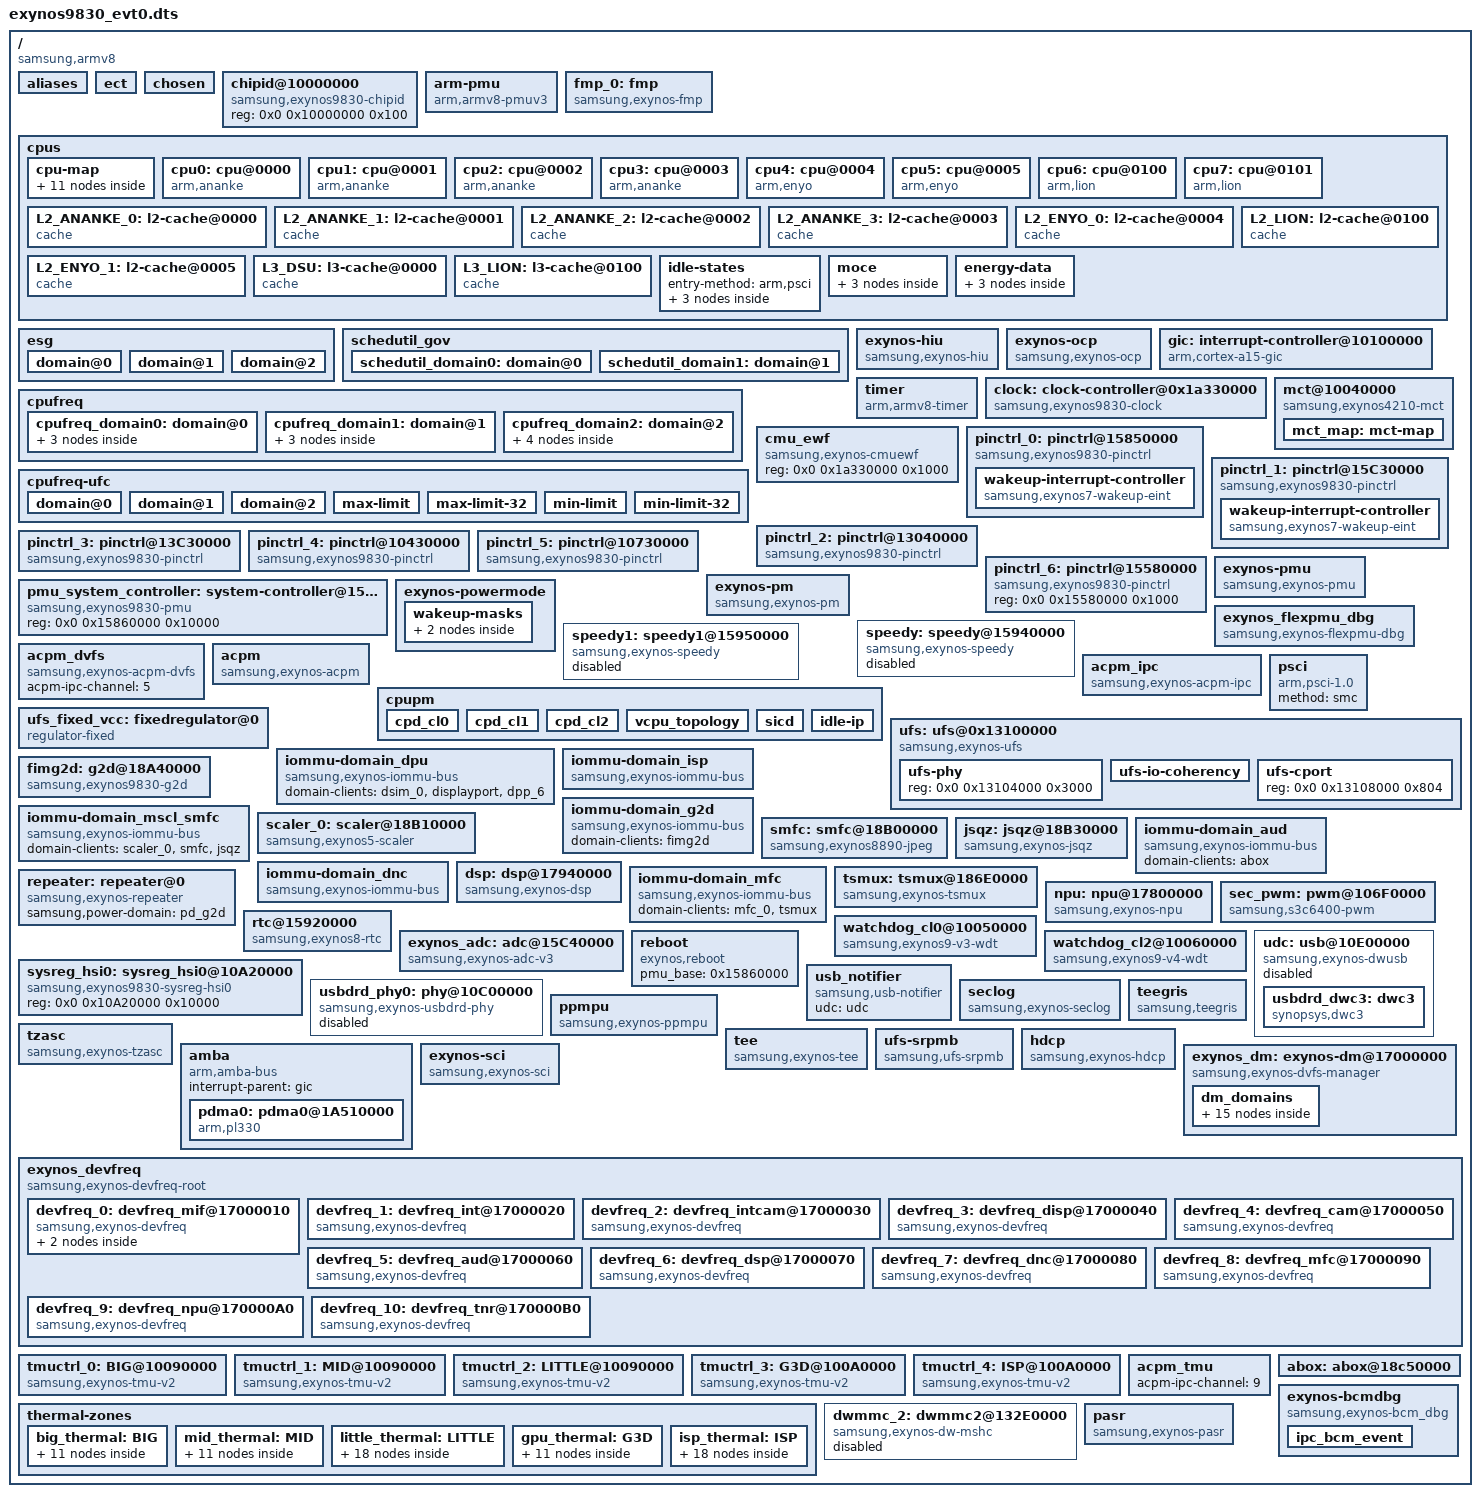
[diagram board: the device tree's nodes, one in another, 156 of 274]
/*
 * SAMSUNG EXYNOS9830 SoC device tree source
 *
 * Copyright (c) 2014 Samsung Electronics Co., Ltd.
 *		http://www.samsung.com
 *
 * SAMSUNG EXYNOS9830 SoC device nodes are listed in this file.
 * EXYNOS based board files can include this file and provide
 * values for board specfic bindings.
 *
 * This program is free software; you can redistribute it and/or modify
 * it under the terms of the GNU General Public License version 2 as
 * published by the Free Software Foundation.
 */

/dts-v1/;
#include <dt-bindings/interrupt-controller/arm-gic.h>
#include <dt-bindings/interrupt-controller/exynos9830_evt0.h>
#include <dt-bindings/soc/samsung/exynos-bcm_dbg.h>
#include "exynos9830-pinctrl.dtsi"
#include "exynos9830-rmem.dtsi"
#include "exynos9830_evt0-sysmmu.dtsi"
#include <dt-bindings/clock/exynos9830_evt0.h>
#include "exynos9830-usi.dtsi"
#include "exynos9830-pm-domains_evt0.dtsi"
#include "exynos9830_evt0-pmucal-dbg.dtsi"
#include "exynos9830-audio.dtsi"
#include <dt-bindings/ufs/ufs.h>
#include "exynos9830-debug.dtsi"
#include "exynos9830-mali.dtsi"
#include "exynos9830_evt0-bts.dtsi"
#include "exynos9830-dpu.dtsi"
#include "exynos9830_evt0-mfc.dtsi"
#include <dt-bindings/soc/samsung/exynos9830-dm.h>
#include <dt-bindings/soc/samsung/exynos9830-devfreq.h>
#include <dt-bindings/thermal/thermal.h>
#include "exynos9830-pcie.dtsi"
#include "exynos9830_evt0-camera.dtsi"
#include "exynos9830-ems.dtsi"

/ {
	compatible = "samsung,armv8", "samsung,exynos990";
	dtb-hw_rev = <0>;
	dtb-hw_rev_end = <255>;
	interrupt-parent = <&gic>;
	#address-cells = <2>;
	#size-cells = <1>;

	aliases {
		pinctrl0 = &pinctrl_0;
		pinctrl1 = &pinctrl_1;
		pinctrl2 = &pinctrl_2;
		pinctrl3 = &pinctrl_3;
		pinctrl4 = &pinctrl_4;
		pinctrl5 = &pinctrl_5;
		pinctrl6 = &pinctrl_6;
		fmp0 = &fmp_0;
		mshc2 = &dwmmc_2;
		scaler0 = &scaler_0;
		mfc0 = &mfc_0;
	};

	ect {
		parameter_address = <0x90000000>;
		parameter_size = <0x4B000>;
	};

	chosen: chosen {
//		bootargs = "earlycon=exynos4210,0x10540000 console=ttySAC0,115200n8 root=/dev/ram0 rw ramdisk=8192 initrd=0x84000000,8M init=/linuxrc mem=512M clk_ignore_unused";
		bootargs = "androidboot.dtbo_idx=0 bcm_setup=0xffffff80f8e00000 pmic_info=0x3 ccic_info=0x1 firmware_class.path=/vendor/firmware reserve-fimc=0xffffff90f9fe0000 nohugeiomap epx_activate=true fpsimd_check_context=y";
		linux,initrd-start = <0x84000000>;
		linux,initrd-end = <0x841FFFFF>;
	};


	chipid@10000000 {
		compatible = "samsung,exynos9830-chipid";
		reg = <0x0 0x10000000 0x100>;
	};

	arm-pmu {
		compatible = "arm,armv8-pmuv3";
		interrupts = <0 INTREQ__CPUCL0_PMUIRQ_0 4>,
			   <0 INTREQ__CPUCL0_PMUIRQ_1 4>,
			   <0 INTREQ__CPUCL0_PMUIRQ_2 4>,
			   <0 INTREQ__CPUCL0_PMUIRQ_3 4>,
			   <0 INTREQ__CPUCL0_PMUIRQ_4 4>,
			   <0 INTREQ__CPUCL0_PMUIRQ_5 4>,
			   <0 INTREQ__CPUCL2_PMUIRQ_0 4>,
			   <0 INTREQ__CPUCL2_PMUIRQ_1 4>;

		interrupt-affinity = <&cpu0>,
					<&cpu1>,
					<&cpu2>,
					<&cpu3>,
					<&cpu4>,
					<&cpu5>,
					<&cpu6>,
					<&cpu7>;
	};

	fmp_0: fmp {
		compatible = "samsung,exynos-fmp";
	};

	cpus {
		#address-cells = <2>;
		#size-cells = <0>;

		cpu-map {
			cluster0 {
				core0 {
					cpu = <&cpu0>;
				};
				core1 {
					cpu = <&cpu1>;
				};
				core2 {
					cpu = <&cpu2>;
				};
				core3 {
					cpu = <&cpu3>;
				};
			};

			cluster1 {
				core0 {
					cpu = <&cpu4>;
				};
				core1 {
					cpu = <&cpu5>;
				};
			};

			cluster2 {
				core0 {
					cpu = <&cpu6>;
				};
				core1 {
					cpu = <&cpu7>;
				};
			};
		};

		cpu0: cpu@0000 {
			device_type = "cpu";
			compatible = "arm,ananke", "arm,armv8";
			reg = <0x0 0x0000>;
			enable-method = "psci";
			cpu-idle-states = <&ANANKE_CPU_SLEEP>;
			sched-energy-data = <&ANANKE_ENERGY>;
			i-cache-size = <0x8000>;	/* 32KB */
			i-cache-line-size = <64>;
			i-cache-sets = <128>;
			d-cache-size = <0x8000>;	/* 32KB */
			d-cache-line-size = <64>;
			d-cache-sets = <128>;
			next-level-cache = <&L2_ANANKE_0>;
		};
		cpu1: cpu@0001 {
			device_type = "cpu";
			compatible = "arm,ananke", "arm,armv8";
			reg = <0x0 0x0001>;
			enable-method = "psci";
			cpu-idle-states = <&ANANKE_CPU_SLEEP>;
			sched-energy-data = <&ANANKE_ENERGY>;
			i-cache-size = <0x8000>;	/* 32KB */
			i-cache-line-size = <64>;
			i-cache-sets = <128>;
			d-cache-size = <0x8000>;	/* 32KB */
			d-cache-line-size = <64>;
			d-cache-sets = <128>;
			next-level-cache = <&L2_ANANKE_1>;
		};
		cpu2: cpu@0002 {
			device_type = "cpu";
			compatible = "arm,ananke", "arm,armv8";
			reg = <0x0 0x0002>;
			enable-method = "psci";
			cpu-idle-states = <&ANANKE_CPU_SLEEP>;
			sched-energy-data = <&ANANKE_ENERGY>;
			i-cache-size = <0x8000>;	/* 32KB */
			i-cache-line-size = <64>;
			i-cache-sets = <128>;
			d-cache-size = <0x8000>;	/* 32KB */
			d-cache-line-size = <64>;
			d-cache-sets = <128>;
			next-level-cache = <&L2_ANANKE_2>;
		};
		cpu3: cpu@0003 {
			device_type = "cpu";
			compatible = "arm,ananke", "arm,armv8";
			reg = <0x0 0x0003>;
			enable-method = "psci";
			cpu-idle-states = <&ANANKE_CPU_SLEEP>;
			sched-energy-data = <&ANANKE_ENERGY>;
			i-cache-size = <0x8000>;	/* 32KB */
			i-cache-line-size = <64>;
			i-cache-sets = <128>;
			d-cache-size = <0x8000>;	/* 32KB */
			d-cache-line-size = <64>;
			d-cache-sets = <128>;
			next-level-cache = <&L2_ANANKE_3>;
		};
		cpu4: cpu@0004 {
			device_type = "cpu";
			compatible = "arm,enyo", "arm,armv8";
			reg = <0x0 0x0004>;
			enable-method = "psci";
			cpu-idle-states = <&ENYO_CPU_SLEEP>;
			sched-energy-data = <&ENYO_ENERGY>;
			i-cache-size = <0x10000>;	/* 64KB */
			i-cache-line-size = <64>;
			i-cache-sets = <256>;
			d-cache-size = <0x10000>;	/* 64KB */
			d-cache-line-size = <64>;
			d-cache-sets = <256>;
			next-level-cache = <&L2_ENYO_0>;
		};
		cpu5: cpu@0005 {
			device_type = "cpu";
			compatible = "arm,enyo", "arm,armv8";
			reg = <0x0 0x0005>;
			enable-method = "psci";
			cpu-idle-states = <&ENYO_CPU_SLEEP>;
			sched-energy-data = <&ENYO_ENERGY>;
			i-cache-size = <0x10000>;	/* 64KB */
			i-cache-line-size = <64>;
			i-cache-sets = <256>;
			d-cache-size = <0x10000>;	/* 64KB */
			d-cache-line-size = <64>;
			d-cache-sets = <256>;
			next-level-cache = <&L2_ENYO_1>;
		};
		cpu6: cpu@0100 {
			device_type = "cpu";
			compatible = "arm,lion", "arm,armv8";
			reg = <0x0 0x0100>;
			enable-method = "psci";
			cpu-idle-states = <&LION_CPU_SLEEP>;
			sched-energy-data = <&LION_ENERGY>;
			i-cache-size = <0x10000>;	/* 64KB */
			i-cache-line-size = <128>;
			i-cache-sets = <128>;
			d-cache-size = <0x10000>;	/* 64KB */
			d-cache-line-size = <64>;
			d-cache-sets = <256>;
			next-level-cache = <&L2_LION>;
		};
		cpu7: cpu@0101 {
			device_type = "cpu";
			compatible = "arm,lion", "arm,armv8";
			reg = <0x0 0x0101>;
			enable-method = "psci";
			cpu-idle-states = <&LION_CPU_SLEEP>;
			sched-energy-data = <&LION_ENERGY>;
			i-cache-size = <0x10000>;	/* 64KB */
			i-cache-line-size = <128>;
			i-cache-sets = <128>;
			d-cache-size = <0x10000>;	/* 64KB */
			d-cache-line-size = <64>;
			d-cache-sets = <256>;
			next-level-cache = <&L2_LION>;
		};

		L2_ANANKE_0: l2-cache@0000 {
			compatible = "cache";
			cache-level = <2>;
			cache-size = <0x10000>;		/* 64KB */
			cache-line-size = <64>;
			cache-sets = <256>;
			next-level-cache = <&L3_DSU>;
		};
		L2_ANANKE_1: l2-cache@0001 {
			compatible = "cache";
			cache-level = <2>;
			cache-size = <0x10000>;		/* 64KB */
			cache-line-size = <64>;
			cache-sets = <256>;
			next-level-cache = <&L3_DSU>;
		};
		L2_ANANKE_2: l2-cache@0002 {
			compatible = "cache";
			cache-level = <2>;
			cache-size = <0x10000>;		/* 64KB */
			cache-line-size = <64>;
			cache-sets = <256>;
			next-level-cache = <&L3_DSU>;
		};
		L2_ANANKE_3: l2-cache@0003 {
			compatible = "cache";
			cache-level = <2>;
			cache-size = <0x10000>;		/* 64KB */
			cache-line-size = <64>;
			cache-sets = <256>;
			next-level-cache = <&L3_DSU>;
		};
		L2_ENYO_0: l2-cache@0004 {
			compatible = "cache";
			cache-level = <2>;
			cache-size = <0x40000>;		/* 256KB */
			cache-line-size = <64>;
			cache-sets = <512>;
			next-level-cache = <&L3_DSU>;
		};
		L2_ENYO_1: l2-cache@0005 {
			compatible = "cache";
			cache-level = <2>;
			cache-size = <0x40000>;		/* 256KB */
			cache-line-size = <64>;
			cache-sets = <512>;
			next-level-cache = <&L3_DSU>;
		};
		L2_LION: l2-cache@0100 {
			compatible = "cache";
			cache-level = <2>;
			cache-size = <0x200000>;	/* 2MB */
			cache-line-size = <64>;
			cache-sets = <4096>;
			next-level-cache = <&L3_LION>;
		};
		L3_DSU: l3-cache@0000 {
			compatible = "cache";
			cache-level = <3>;
			cache-line-size = <64>;
			cache-sets = <1024>;
			cache-size = <0x100000>;	/* 1MB */
		};
		L3_LION: l3-cache@0100 {
			compatible = "cache";
			cache-level = <3>;
			cache-line-size = <64>;
			cache-sets = <4096>;
			cache-size = <0x300000>;	/* 3MB */
		};

		idle-states {
			entry-method = "arm,psci";

			ANANKE_CPU_SLEEP: ananke-cpu-sleep {
				idle-state-name = "c2";
				compatible = "exynos,idle-state";
				arm,psci-suspend-param = <0x0010000>;
				entry-latency-us = <70>;
				exit-latency-us = <160>;
				min-residency-us = <2000>;
				status = "okay";
				moce-weights = <100>;
				moce-factors = <&ANANKE_FREQ_FACTOR>;
			};

			ENYO_CPU_SLEEP: enyo-cpu-sleep {
				idle-state-name = "c2";
				compatible = "exynos,idle-state";
				arm,psci-suspend-param = <0x0010000>;
				entry-latency-us = <150>;
				exit-latency-us = <190>;
				min-residency-us = <2500>;
				status = "okay";
				moce-weights = <100>;
				moce-factors = <&ENYO_FREQ_FACTOR>;
			};

			LION_CPU_SLEEP: lion-cpu-sleep {
				idle-state-name = "c2";
				compatible = "exynos,idle-state";
				arm,psci-suspend-param = <0x0010000>;
				entry-latency-us = <235>;
				exit-latency-us = <220>;
				min-residency-us = <3500>;
				status = "okay";
				moce-weights = <100>;
				moce-factors = <&LION_FREQ_FACTOR>;
			};
		};

		moce {
			/* factor table format: [ratio][factor][ratio]...[ratio] */
			ANANKE_FREQ_FACTOR: ananke-freq-factor {
				domain = <0>;
				type = <0>;
				ratio-table = <100>;
			};
			ENYO_FREQ_FACTOR: enyo-freq-factor {
				domain = <1>;
				type = <0>;
				ratio-table = <100>;
			};
			LION_FREQ_FACTOR: lion-freq-factor {
				domain = <2>;
				type = <0>;
				ratio-table = <100>;
			};
		};

		energy-data {
			ANANKE_ENERGY: ananke-energy {
				mips-per-mhz = <2776>;
				power-coefficient = <112>;
				mips-per-mhz-s = <2221>;
				power-coefficient-s = <99>;
				static-power-coefficient = <56>;

				efficiency-weight = <100>;
				efficiency-weight-perf = <200>;
			};
			ENYO_ENERGY: enyo-energy {
				mips-per-mhz = <6618>;
				power-coefficient = <331>;
				mips-per-mhz-s = <4434>;
				power-coefficient-s = <258>;
				static-power-coefficient = <69>;

				efficiency-weight = <200>;
				efficiency-weight-perf = <200>;
			};
			LION_ENERGY: lion-energy {
				mips-per-mhz = <8248>;
				power-coefficient = <908>;
				mips-per-mhz-s = <3382>;
				power-coefficient-s = <590>;
				static-power-coefficient = <291>;

				efficiency-weight = <33>;
				efficiency-weight-perf = <300>;
			};
		};
	};

	esg {
		domain@0 {
			device_type = "esgov-pol0";
			shared-cpus = "0-3";
			pm_qos-min-class = <3>;
			pm_qos-max-class = <4>;
			step = <10>;
		};
		domain@1 {
			device_type = "esgov-pol4";
			shared-cpus = "4-5";
			pm_qos-min-class = <5>;
			pm_qos-max-class = <6>;
			step = <8>;
		};
		domain@2 {
			device_type = "esgov-pol6";
			shared-cpus = "6-7";
			pm_qos-min-class = <7>;
			pm_qos-max-class = <8>;
			step = <10>;
		};
	};

	schedutil_gov {
		schedutil_domain0: domain@0 {
			device_type = "schedutil-domain";
			shared-cpus = "0-3";

			enabled = <0>;          /* Disabled */
			qos_min_class = <3>;
		};

		schedutil_domain1: domain@1 {
			device_type = "schedutil-domain";
			shared-cpus = "4-5";

			enabled = <1>;          /* Enabled */
			expired_time = <80>;    /* 80ms */
			qos_min_class = <5>;
		};
	};

	cpufreq {
		cpufreq_domain0: domain@0 {
			device_type = "cpufreq-domain";
			sibling-cpus = "0-3";
			cal-id = <ACPM_DVFS_CPUCL0>;
			dm-type = <DM_CPU_CL0>;

			max-freq = <1586000>;
			min-freq = <182000>;

			/* PM QoS Class ID*/
			pm_qos-min-class = <3>;
			pm_qos-max-class = <4>;

			user-default-qos = <806000>;
			user-boost = <0>;

			#cooling-cells = <2>; /* min followed by max */

			dm-constraints {
				mif-perf {
					const-type = <CONSTRAINT_MIN>;
					dm-type = <DM_MIF>;
						/* cpu      mif */
					table = < 2106000 0
						2002000 0
						1950000 0
						1846000 0
						1742000 0
						1586000 0
						1456000 0
						1300000 0
						1157000 0
						1053000 0
						 949000 0
						 806000 0
						 650000 0
						 546000 0
						 442000 0
						 351000 0
						 182000 0
						>;
				};
			};

			slack_timer {
				device_type = "slack-timer-domain";
			};
		};

		cpufreq_domain1: domain@1 {
			device_type = "cpufreq-domain";
			sibling-cpus = "4-5";
			cal-id = <ACPM_DVFS_CPUCL1>;
			dm-type = <DM_CPU_CL1>;

			max-freq = <1898000>;
			min-freq = <377000>;

			/* PM QoS Class ID*/
			pm_qos-min-class = <5>;
			pm_qos-max-class = <6>;

			user-default-qos = <845000>;
			user-boost = <1>;

			#cooling-cells = <2>; /* min followed by max */

			dm-constraints {
				mif-perf {
					const-type = <CONSTRAINT_MIN>;
					dm-type = <DM_MIF>;
						/* cpu     mif */
					table = < 2600000 1794000
						2504000 1794000
						2400000 1794000
						2314000 1794000
						2210000 1794000
						2106000 1539000
						2002000 1539000
						1898000 0
						1794000 0
						1690000 0
						1586000 0
						1508000 0
						1404000 0
						1222000 0
						1066000 0
						 962000 0
						 845000 0
						 754000 0
						 650000 0
						 507000 0
						 377000 0
						>;
				};
			};

			slack_timer {
				device_type = "slack-timer-domain";
				expired_time = <80>;    /* 80ms */
			};
		};

		cpufreq_domain2: domain@2 {
			device_type = "cpufreq-domain";
			sibling-cpus = "6-7";
			cal-id = <ACPM_DVFS_CPUCL2>;
			dm-type = <DM_CPU_CL2>;
			need-awake;

			max-freq = <1482000>;
			min-freq = <546000>;

			/* PM QoS Class ID*/
			pm_qos-min-class = <7>;
			pm_qos-max-class = <8>;

			user-default-qos = <962000>;
			user-boost = <2>;

			#cooling-cells = <2>; /* min followed by max */

			dm-constraints {
				mif-perf {
					const-type = <CONSTRAINT_MIN>;
					dm-type = <DM_MIF>;
					/*  cpu     mif  */
					table = < 3016000 1794000
						2834000 1794000
						2730000 1794000
						2626000 1794000
						2522000 1794000
						2418000 1794000
						2314000 1794000
						2210000 1794000
						2002000 1539000
						1898000 0
						1794000 0
						1690000 0
						1586000 0
						1482000 0
						1378000 0
						1274000 0
						1170000 0
						1066000 0
						962000  0
						888000 0
						754000 0
						650000 0
						546000 0
						>;
				};
				mif-skew {
					guidance;
					const-type = <CONSTRAINT_MIN>;
					dm-type = <DM_MIF>;
					ect-name = "CPUCL2";
				};
			};

			slack_timer {
				device_type = "slack-timer-domain";

				enabled = <1>;          /* Enabled */
				expired_time = <80>;    /* 80ms */
			};
		};
	};

	cpufreq-ufc {
		/* Ctrl Type */
		#define PM_QOS_MIN_LIMIT		0
		#define PM_QOS_MIN_WO_BOOST_LIMIT	1
		#define PM_QOS_MAX_LIMIT		2
		/* Execution Mode */
		#define AARCH64_MODE			0
		#define AARCH32_MODE			1

		device_type = "cpufreq_ufc";
		table-col = <4>;
		table-row = <42>;

		domain@0 {
			device_type = "ufc_domain";
			shared-cpus = "0-3";
			pm_qos-min-class = <3>;
			pm_qos-max-class = <4>;
		};
		domain@1 {
			device_type = "ufc_domain";
			shared-cpus = "4-5";
			pm_qos-min-class = <5>;
			pm_qos-max-class = <6>;
		};
		domain@2 {
			device_type = "ufc_domain";
			shared-cpus = "6-7";
			pm_qos-min-class = <7>;
			pm_qos-max-class = <8>;
		};
		max-limit {
			device_type = "ufc_table";
			ctrl-type = <PM_QOS_MAX_LIMIT>;
			sse-mode = <AARCH64_MODE>;
			      /* Vfreq    big      Med	Lit */
			table = <
				2730000	2730000	2600000	2002000
				2623359	2626000	2600000	2002000
				2519384	2522000	2600000	2002000
				2415410	2418000	2600000	2002000
				2311435	2314000	2600000	2002000
				2207460	2210000	2600000	2002000
				2170136	2106000	2600000	2002000
				2103486	2002000	2600000	2002000
				2090156	1898000	2600000	2002000
				2002177	1794000	2600000	2002000
				1999511	1794000	2504000	2002000
				1930195	1690000	2504000	2002000
				1895537	1690000	2400000	2002000
				1844882	1586000	2400000	2002000
				1791562	1482000	2400000	2002000
				1756904	1482000	2314000	2002000
				1687587	1378000	2314000	2002000
				1671591	1378000	2210000	2002000
				1599609	1274000	2210000	1950000
				1583613	1170000	2210000	1846000
				1495634	1170000	2106000	1846000
				1479638	1066000	2106000	1846000
				1410322	962000	2106000	1742000
				1375664	962000	2106000	1742000
				1322343	962000	2002000	1742000
				1271689	962000	2002000	1742000
				1258359	962000	2002000	1742000
				1170380	888000	2002000	1742000
				1167714	888000	2002000	1586000
				1063740	888000	1898000	1586000
				1018417	888000	1794000	1456000
				959765	888000	1690000	1456000
				887783	888000	1586000	1300000
				855791	888000	1508000	1300000
				802470	888000	1404000	1300000
				751816	888000	1222000	1300000
				703828	754000	1066000	1300000
				647841	0	962000	1300000
				629179	0	845000	1300000
				543867	0	754000	1300000
				541201	0	650000	1300000
				421230	0	507000	1300000
				/* filled little freq automatically */
				>;
		};
		max-limit-32 {
			device_type = "ufc_table";
			ctrl-type = <PM_QOS_MAX_LIMIT>;
			sse-mode = <AARCH32_MODE>;
			      /* Vfreq    big      Lit */
			table = <
				2730000	2730000	2600000	2002000
				2623359	2626000	2600000	2002000
				2519384	2522000	2600000	2002000
				2415410	2418000	2600000	2002000
				2311435	2314000	2600000	2002000
				2207460	2210000	2600000	2002000
				2170136	2106000	2600000	2002000
				2103486	2002000	2600000	2002000
				2090156	1898000	2600000	2002000
				2002177	1794000	2600000	2002000
				1999511	1690000	2600000	2002000
				1930195	1586000	2600000	2002000
				1895537	1586000	2504000	2002000
				1844882	1482000	2504000	2002000
				1791562	1482000	2400000	2002000
				1756904	1378000	2400000	2002000
				1687587	1274000	2400000	2002000
				1671591	1170000	2400000	2002000
				1599609	1170000	2314000	2002000
				1583613	1066000	2314000	2002000
				1495634	962000	2314000	2002000
				1479638	962000	2210000	2002000
				1410322	888000	2210000	2002000
				1375664	754000	2210000	2002000
				1322343	754000	2210000	2002000
				1271689	754000	2210000	2002000
				1258359	754000	2210000	2002000
				1170380	754000	2106000	1950000
				1167714	754000	2002000	1846000
				1063740	754000	1898000	1742000
				1018417	754000	1794000	1586000
				959765	754000	1690000	1586000
				887783	754000	1586000	1456000
				855791	754000	1508000	1456000
				802470	754000	1404000	1456000
				751816	754000	1222000	1300000
				703828	754000	1066000	1300000
				647841	0	962000	1300000
				629179	0	845000	1300000
				543867	0	754000	1300000
				541201	0	650000	1300000
				421230	0	507000	1300000
				/* filled little freq automatically */
				>;
		};
		min-limit {
			device_type = "ufc_table";
			ctrl-type = <PM_QOS_MIN_LIMIT>;
			sse-mode = <AARCH64_MODE>;
			      /* Vfreq    big      Lit */
			table = <
				2730000	2730000	2600000	2002000
				2623359	2626000	2600000	2002000
				2519384	2522000	2600000	2002000
				2415410	2418000	2600000	2002000
				2311435	2314000	2600000	2002000
				2207460	2210000	2600000	2002000
				2170136	2210000	2600000	2002000
				2103486	2106000	2600000	2002000
				2090156	2106000	2504000	2002000
				2002177	2106000	2400000	2002000
				1999511	2002000	2400000	2002000
				1930195	2002000	2314000	2002000
				1895537	1898000	2314000	806000
				1844882	1898000	2210000	806000
				1791562	1794000	2210000	806000
				1756904	1794000	2106000	806000
				1687587	1690000	2106000	806000
				1671591	1690000	2002000	806000
				1599609	1690000	1898000	806000
				1583613	1586000	1898000	806000
				1495634	1586000	1794000	806000
				1479638	1482000	1794000	806000
				1410322	1482000	1690000	806000
				1375664	1378000	1690000	806000
				1322343	1378000	1586000	806000
				1271689	1274000	1586000	806000
				1258359	1274000	1508000	806000
				1170380	1274000	1404000	806000
				1167714	1170000	1404000	806000
				1063740	1066000	1404000	806000
				1018417	1066000	1222000	806000
				959765	962000	1222000	806000
				887783	962000	1066000	806000
				855791	888000	1066000	806000
				802470	888000	962000	806000
				751816	754000	962000	806000
				703828	754000	845000	806000
				647841	650000	845000	806000
				629179	650000	754000	806000
				543867	546000	754000	806000
				541201	546000	650000	806000
				421230	546000	507000	806000
				/* filled little freq automatically */
				>;
		};
		min-limit-32 {
			device_type = "ufc_table";
			ctrl-type = <PM_QOS_MIN_LIMIT>;
			sse-mode = <AARCH32_MODE>;
			table = <
				2730000	2730000	2600000	2002000
				2623359	2626000	2600000	2002000
				2519384	2626000	2600000	2002000
				2415410	2522000	2600000	2002000
				2311435	2522000	2504000	2002000
				2207460	2418000	2504000	2002000
				2170136	2418000	2400000	2002000
				2103486	2418000	2314000	2002000
				2090156	2314000	2314000	2002000
				2002177	2314000	2210000	2002000
				1999511	2210000	2210000	2002000
				1930195	2210000	2106000	2002000
				1895537	2106000	2106000	806000
				1844882	2106000	2002000	806000
				1791562	2002000	2002000	806000
				1756904	2002000	1898000	806000
				1687587	1898000	1898000	806000
				1671591	1898000	1794000	806000
				1599609	1794000	1794000	806000
				1583613	1794000	1690000	806000
				1495634	1690000	1690000	806000
				1479638	1690000	1586000	806000
				1410322	1586000	1586000	806000
				1375664	1586000	1508000	806000
				1322343	1482000	1508000	806000
				1271689	1482000	1404000	806000
				1258359	1378000	1404000	806000
				1170380	1274000	1404000	806000
				1167714	1274000	1222000	806000
				1063740	1170000	1222000	806000
				1018417	1170000	1066000	806000
				959765	1066000	1066000	806000
				887783	1066000	962000	806000
				855791	962000	962000	806000
				802470	888000	962000	806000
				751816	888000	845000	806000
				703828	888000	754000	806000
				647841	754000	754000	806000
				629179	754000	650000	806000
				543867	650000	650000	806000
				541201	546000	650000	806000
				421230	546000	507000	806000
				/* filled little freq automatically */
				>;
		};
	};

	exynos-hiu {
		compatible = "samsung,exynos-hiu";
		interrupts = <GIC_SPI INTREQ__CPUCL2_GCUIRQ IRQ_TYPE_LEVEL_HIGH>;
		boost-threshold = <1482000>;
		boost-max = <1482000>;
		cal-id = <ACPM_DVFS_CPUCL2>;
		sw-pbl = <0x57>;
		bl1-inc = <0>;
		bl2-inc = <0>;
		bl3-inc = <0>;
		tb-enabled;
		operation-mode = <0>;
		sibling-cpus = "6-7";
				/* PB  BL  PBL  PWR_THR_INC */
		config-table = <0x0 0x0 0x57 0x0        /* config A */
				0x1 0x2 0x79 0x0        /* config B */
				0x0 0x0 0x57 0x0        /* config C */
				0x0 0x0 0x57 0x0        /* config D */
				0x1 0x2 0x79 0x0        /* config E */
				0x0 0x0 0x57 0x0        /* config F */
				0x0 0x0 0x57 0x0        /* config G */
				0x1 0x2 0x79 0x0>;      /* config H */
	};

	exynos-ocp {
		compatible = "samsung,exynos-ocp";

		interrupts = <GIC_SPI INTREQ__CPUCL2_GCUIRQ IRQ_TYPE_LEVEL_HIGH>;

		sibling-cpus = "6-7";
		down-step = <1>;

		max-freq-wo-ocp = <1482000>;

		release-mode = <1>;             /* 0 : current meter, 1 : cpu utilization */
		release-threshold = <50>;       /* @current meter : current(A), @cpu load : capacity ratio(%) */
		release-duration = <15>;        /* msec */
	};


	gic:interrupt-controller@10100000 {
		compatible = "arm,cortex-a15-gic", "arm,cortex-a9-gic";
		#interrupt-cells = <3>;
		#address-cells = <0>;
		interrupt-controller;
		reg =	<0x0 0x10101000 0x1000>,
			<0x0 0x10102000 0x1000>,
			<0x0 0x10104000 0x2000>,
			<0x0 0x10106000 0x2000>;
		interrupts = <GIC_PPI 9 (GIC_CPU_MASK_SIMPLE(4) | IRQ_TYPE_LEVEL_HIGH)>;
	};

	timer {
	        compatible = "arm,armv8-timer";
		interrupts = <GIC_PPI 13
				(GIC_CPU_MASK_SIMPLE(8) | IRQ_TYPE_LEVEL_LOW)>,
			     <GIC_PPI 14
				(GIC_CPU_MASK_SIMPLE(8) | IRQ_TYPE_LEVEL_LOW)>,
			     <GIC_PPI 11
				(GIC_CPU_MASK_SIMPLE(8) | IRQ_TYPE_LEVEL_LOW)>,
			     <GIC_PPI 10
				(GIC_CPU_MASK_SIMPLE(8) | IRQ_TYPE_LEVEL_LOW)>;
	        clock-frequency = <26000000>;
		use-clocksource-only;
	};

	clock: clock-controller@0x1a330000 {
		compatible = "samsung,exynos9830-clock";
		reg = <0x0 0x1a330000 0x8000>;
		#clock-cells = <1>;
		acpm-ipc-channel = <0>;
	};

	cmu_ewf {
		compatible = "samsung,exynos-cmuewf";
		#address-cells = <2>;
		#size-cells = <1>;
		reg = <0x0 0x1a330000 0x1000>;
	};

	mct@10040000 {
		compatible = "samsung,exynos4210-mct";
		reg = <0x0 0x10040000 0x800>;
		interrupt-controller;
		#interrupt-cells = <1>;
		interrupt-parent = <&mct_map>;
		interrupts =	<0>, <1>, <2>, <3>,
				<4>, <5>, <6>, <7>,
				<8>, <9>, <10>, <11>;
		clocks = <&clock 1>, <&clock 15>;
		clock-names = "fin_pll", "mct";
		use-clockevent-only;

		mct_map: mct-map {
			#interrupt-cells = <1>;
			#address-cells = <0>;
			#size-cells = <0>;
			interrupt-map = <0 &gic 0 INTREQ__MCT_G0 IRQ_TYPE_LEVEL_HIGH>,
					<1 &gic 0 INTREQ__MCT_G1 IRQ_TYPE_LEVEL_HIGH>,
					<2 &gic 0 INTREQ__MCT_G2 IRQ_TYPE_LEVEL_HIGH>,
					<3 &gic 0 INTREQ__MCT_G3 IRQ_TYPE_LEVEL_HIGH>,
					<4 &gic 0 INTREQ__MCT_L0 IRQ_TYPE_LEVEL_HIGH>,
					<5 &gic 0 INTREQ__MCT_L1 IRQ_TYPE_LEVEL_HIGH>,
					<6 &gic 0 INTREQ__MCT_L2 IRQ_TYPE_LEVEL_HIGH>,
					<7 &gic 0 INTREQ__MCT_L3 IRQ_TYPE_LEVEL_HIGH>,
					<8 &gic 0 INTREQ__MCT_L4 IRQ_TYPE_LEVEL_HIGH>,
					<9 &gic 0 INTREQ__MCT_L5 IRQ_TYPE_LEVEL_HIGH>,
					<10 &gic 0 INTREQ__MCT_L6 IRQ_TYPE_LEVEL_HIGH>,
					<11 &gic 0 INTREQ__MCT_L7 IRQ_TYPE_LEVEL_HIGH>;
		};
	};

	/* ALIVE */
	pinctrl_0: pinctrl@15850000 {
		compatible = "samsung,exynos9830-pinctrl";
		reg = <0x0 0x15850000 0x1000>;
		interrupts = <GIC_SPI INTREQ__ALIVE_EINT0 IRQ_TYPE_LEVEL_HIGH>, <GIC_SPI INTREQ__ALIVE_EINT1 IRQ_TYPE_LEVEL_HIGH>,
			     <GIC_SPI INTREQ__ALIVE_EINT2 IRQ_TYPE_LEVEL_HIGH>, <GIC_SPI INTREQ__ALIVE_EINT3 IRQ_TYPE_LEVEL_HIGH>,
			     <GIC_SPI INTREQ__ALIVE_EINT4 IRQ_TYPE_LEVEL_HIGH>, <GIC_SPI INTREQ__ALIVE_EINT5 IRQ_TYPE_LEVEL_HIGH>,
			     <GIC_SPI INTREQ__ALIVE_EINT6 IRQ_TYPE_LEVEL_HIGH>, <GIC_SPI INTREQ__ALIVE_EINT7 IRQ_TYPE_LEVEL_HIGH>,
			     <GIC_SPI INTREQ__ALIVE_EINT8 IRQ_TYPE_LEVEL_HIGH>, <GIC_SPI INTREQ__ALIVE_EINT9 IRQ_TYPE_LEVEL_HIGH>,
			     <GIC_SPI INTREQ__ALIVE_EINT10 IRQ_TYPE_LEVEL_HIGH>, <GIC_SPI INTREQ__ALIVE_EINT11 IRQ_TYPE_LEVEL_HIGH>,
			     <GIC_SPI INTREQ__ALIVE_EINT12 IRQ_TYPE_LEVEL_HIGH>, <GIC_SPI INTREQ__ALIVE_EINT13 IRQ_TYPE_LEVEL_HIGH>,
			     <GIC_SPI INTREQ__ALIVE_EINT14 IRQ_TYPE_LEVEL_HIGH>, <GIC_SPI INTREQ__ALIVE_EINT15 IRQ_TYPE_LEVEL_HIGH>,
			     <GIC_SPI INTREQ__ALIVE_EINT16 IRQ_TYPE_LEVEL_HIGH>, <GIC_SPI INTREQ__ALIVE_EINT17 IRQ_TYPE_LEVEL_HIGH>,
			     <GIC_SPI INTREQ__ALIVE_EINT18 IRQ_TYPE_LEVEL_HIGH>, <GIC_SPI INTREQ__ALIVE_EINT19 IRQ_TYPE_LEVEL_HIGH>,
			     <GIC_SPI INTREQ__ALIVE_EINT20 IRQ_TYPE_LEVEL_HIGH>, <GIC_SPI INTREQ__ALIVE_EINT21 IRQ_TYPE_LEVEL_HIGH>,
			     <GIC_SPI INTREQ__ALIVE_EINT22 IRQ_TYPE_LEVEL_HIGH>, <GIC_SPI INTREQ__ALIVE_EINT23 IRQ_TYPE_LEVEL_HIGH>,
			     <GIC_SPI INTREQ__ALIVE_EINT24 IRQ_TYPE_LEVEL_HIGH>, <GIC_SPI INTREQ__ALIVE_EINT25 IRQ_TYPE_LEVEL_HIGH>,
			     <GIC_SPI INTREQ__ALIVE_EINT26 IRQ_TYPE_LEVEL_HIGH>, <GIC_SPI INTREQ__ALIVE_EINT27 IRQ_TYPE_LEVEL_HIGH>,
			     <GIC_SPI INTREQ__ALIVE_EINT28 IRQ_TYPE_LEVEL_HIGH>, <GIC_SPI INTREQ__ALIVE_EINT29 IRQ_TYPE_LEVEL_HIGH>,
			     <GIC_SPI INTREQ__ALIVE_EINT30 IRQ_TYPE_LEVEL_HIGH>, <GIC_SPI INTREQ__ALIVE_EINT31 IRQ_TYPE_LEVEL_HIGH>,
			     <GIC_SPI INTREQ__ALIVE_EINT32 IRQ_TYPE_LEVEL_HIGH>, <GIC_SPI INTREQ__ALIVE_EINT33 IRQ_TYPE_LEVEL_HIGH>;

		wakeup-interrupt-controller {
			compatible = "samsung,exynos7-wakeup-eint";
		};
	};

	/* CMGP */
	pinctrl_1: pinctrl@15C30000{
		compatible = "samsung,exynos9830-pinctrl";
		reg = <0x0 0x15C30000 0x1000>;
		interrupts = <GIC_SPI INTREQ__EXT_INTM04 IRQ_TYPE_LEVEL_HIGH>, <GIC_SPI INTREQ__EXT_INTM05 IRQ_TYPE_LEVEL_HIGH>,
			     <GIC_SPI INTREQ__EXT_INTM06 IRQ_TYPE_LEVEL_HIGH>, <GIC_SPI INTREQ__EXT_INTM07 IRQ_TYPE_LEVEL_HIGH>,
			     <GIC_SPI INTREQ__EXT_INTM08 IRQ_TYPE_LEVEL_HIGH>, <GIC_SPI INTREQ__EXT_INTM09 IRQ_TYPE_LEVEL_HIGH>,
			     <GIC_SPI INTREQ__EXT_INTM10 IRQ_TYPE_LEVEL_HIGH>, <GIC_SPI INTREQ__EXT_INTM11 IRQ_TYPE_LEVEL_HIGH>,
			     <GIC_SPI INTREQ__EXT_INTM12 IRQ_TYPE_LEVEL_HIGH>, <GIC_SPI INTREQ__EXT_INTM13 IRQ_TYPE_LEVEL_HIGH>,
			     <GIC_SPI INTREQ__EXT_INTM14 IRQ_TYPE_LEVEL_HIGH>, <GIC_SPI INTREQ__EXT_INTM15 IRQ_TYPE_LEVEL_HIGH>,
			     <GIC_SPI INTREQ__EXT_INTM16 IRQ_TYPE_LEVEL_HIGH>, <GIC_SPI INTREQ__EXT_INTM17 IRQ_TYPE_LEVEL_HIGH>,
			     <GIC_SPI INTREQ__EXT_INTM18 IRQ_TYPE_LEVEL_HIGH>, <GIC_SPI INTREQ__EXT_INTM19 IRQ_TYPE_LEVEL_HIGH>,
			     <GIC_SPI INTREQ__EXT_INTM20 IRQ_TYPE_LEVEL_HIGH>, <GIC_SPI INTREQ__EXT_INTM21 IRQ_TYPE_LEVEL_HIGH>,
			     <GIC_SPI INTREQ__EXT_INTM22 IRQ_TYPE_LEVEL_HIGH>, <GIC_SPI INTREQ__EXT_INTM23 IRQ_TYPE_LEVEL_HIGH>,
			     <GIC_SPI INTREQ__EXT_INTM24 IRQ_TYPE_LEVEL_HIGH>, <GIC_SPI INTREQ__EXT_INTM25 IRQ_TYPE_LEVEL_HIGH>,
			     <GIC_SPI INTREQ__EXT_INTM26 IRQ_TYPE_LEVEL_HIGH>, <GIC_SPI INTREQ__EXT_INTM27 IRQ_TYPE_LEVEL_HIGH>,
			     <GIC_SPI INTREQ__EXT_INTM28 IRQ_TYPE_LEVEL_HIGH>, <GIC_SPI INTREQ__EXT_INTM29 IRQ_TYPE_LEVEL_HIGH>,
			     <GIC_SPI INTREQ__EXT_INTM30 IRQ_TYPE_LEVEL_HIGH>, <GIC_SPI INTREQ__EXT_INTM31 IRQ_TYPE_LEVEL_HIGH>,
			     <GIC_SPI INTREQ__EXT_INTM31 IRQ_TYPE_LEVEL_HIGH>, <GIC_SPI INTREQ__EXT_INTM32 IRQ_TYPE_LEVEL_HIGH>,
			     <GIC_SPI INTREQ__EXT_INTM33 IRQ_TYPE_LEVEL_HIGH>;

		wakeup-interrupt-controller {
			compatible = "samsung,exynos7-wakeup-eint";
		};
	};

	/* HSI1 */
	pinctrl_2: pinctrl@13040000 {
		compatible = "samsung,exynos9830-pinctrl";
		reg = <0x0 0x13040000 0x1000>;
		interrupts = <GIC_SPI INTREQ__GPIO_HSI1 IRQ_TYPE_LEVEL_HIGH>;
	};

	/* HSI2 */
	pinctrl_3: pinctrl@13C30000 {
		compatible = "samsung,exynos9830-pinctrl";
		reg = <0x0 0x13C30000 0x1000>;
		interrupts = <GIC_SPI INTREQ__GPIO_HSI2 IRQ_TYPE_LEVEL_HIGH>;
	};

	/* PERIC0 */
	pinctrl_4: pinctrl@10430000 {
		compatible = "samsung,exynos9830-pinctrl";
		reg = <0x0 0x10430000 0x1000>;
		interrupts = <GIC_SPI INTREQ__GPIO_PERIC0 IRQ_TYPE_LEVEL_HIGH>;
	};

	/* PERIC1 */
	pinctrl_5: pinctrl@10730000 {
		compatible = "samsung,exynos9830-pinctrl";
		reg = <0x0 0x10730000 0x1000>;
		interrupts = <GIC_SPI INTREQ__GPIO_PERIC1 IRQ_TYPE_LEVEL_HIGH>;
	};

	/* VTS */
	pinctrl_6: pinctrl@15580000 {
		compatible = "samsung,exynos9830-pinctrl";
		reg = <0x0 0x15580000 0x1000>;
	};

	exynos-pmu {
		compatible = "samsung,exynos-pmu";
		samsung,syscon-phandle = <&pmu_system_controller>;
		reg = <0x0 0x15860000 0x10000>;
		reg-names = "pmu_alive";
	};

	pmu_system_controller: system-controller@15860000 {
		compatible = "samsung,exynos9830-pmu", "syscon";
		reg = <0x0 0x15860000 0x10000>;
	};

	exynos-pm {
		compatible = "samsung,exynos-pm";
		reg = <0x0 0x15850000 0x1000>,
		    <0x0 0x10101200 0x100>;
		reg-names = "gpio_alive_base",
			"gicd_ispendrn_base";
		num-eint = <34>;
		num-gic = <16>;
		suspend_mode_idx = <8>;         /* SYS_SLEEP */
		suspend_psci_idx = <1024>;      /* PSCI_SYSTEM_SLEEP */
		cp_call_mode_idx = <10>;        /* SYS_SLEEP_AUD_ON */
		cp_call_psci_idx = <1024>;      /* PSCI_SYSTEM_SLEEP */

		usbl2_suspend_available = <0>;  /* SYS_SLEEP_USBL2 */
		usbl2_suspend_mode_idx = <13>;  /* PSCI_SYSTEM_SLEEP */

		/* WAKEUP_STAT,      WAKEUP2_STAT*/
		wakeup_stat = <0x3950>,         <0x3954>;

		wake_lock = <0>;		/* 1: held wake_lock */
	};

	exynos-powermode {
		wakeup-masks {
			/*
			 * wakeup_mask configuration
			 *              SICD            SICD_CPD        AFTR            STOP
			 *              LPD             LPA             ALPA            DSTOP
			 *              SLEEP           SLEEP_VTS_ON    SLEEP_AUD_ON    FAPO
			 *              USB_L2		SYS_SLEEP_HSI2ON
			 */
			wakeup-mask {
				mask = <0x7ff81aff>,    <0x0>,          <0x0>,          <0x0>,
				       <0x0>,           <0x0>,          <0x0>,          <0x0>,
				       <0x81a6f>,        <0x1a6f>,       <0x1a6f>,       <0x0>,
				       <0x0>,		<0x81a6f>;
				mask-offset = <0x3944>;
				stat-offset = <0x3950>;
			};
			wakeup-mask2 {
				mask = <0xf>,           <0x0>,          <0x0>,          <0x0>,
				       <0x0>,           <0x0>,          <0x0>,          <0x0>,
				       <0xf>,           <0xf>,          <0xf>,          <0x0>,
				       <0x0>, 		<0xc>;
				mask-offset = <0x3964>;
				stat-offset = <0x3954>;
				usbl2_wakeup_int_en = <2>, <3>;
			};
		};
	};

	exynos_flexpmu_dbg {
		compatible = "samsung,exynos-flexpmu-dbg";
		#address-cells = <2>;
		#size-cells = <1>;
		data-base = <0x2051c00>;
		data-size = <0x400>;
		reg = <0x0 0x15920000 0x1000>;
	};

	speedy: speedy@15940000 {
		compatible = "samsung,exynos-speedy";
		reg = <0x0 0x15940000 0x2000>;
		interrupts = <GIC_SPI INTREQ__SPEEDY_APM IRQ_TYPE_LEVEL_HIGH>;
		#address-cells = <1>;
		#size-cells = <0>;
		pinctrl-names = "default";
		pinctrl-0 = <&speedy_bus>;
		status = "disabled";
	};

	speedy1: speedy1@15950000 {
		compatible = "samsung,exynos-speedy";
		reg = <0x0 0x15950000 0x2000>;
		interrupts = <GIC_SPI INTREQ__SPEEDY_SUB_APM IRQ_TYPE_LEVEL_HIGH>;
		#address-cells = <1>;
		#size-cells = <0>;
		pinctrl-names = "default";
		pinctrl-0 = <&speedy1_bus>;
		status = "disabled";
	};

	acpm_dvfs {
		compatible = "samsung,exynos-acpm-dvfs";
		acpm-ipc-channel = <5>;
	};

	acpm {
		compatible = "samsung,exynos-acpm";
		#address-cells = <2>;
		#size-cells = <1>;
		acpm-ipc-channel = <4>;
		fvmap_offset = <0xBC00>;
		reg = <0x0 0x15830000 0x1000>;		/* TIMER_APM */
		reg-names = "timer_apm";
		peritimer-cnt = <0xFFFF>;
	};

	acpm_ipc {
		compatible = "samsung,exynos-acpm-ipc";
		#address-cells = <2>;
		#size-cells = <1>;
		interrupts = <GIC_SPI INTREQ__MAILBOX_APM2AP IRQ_TYPE_LEVEL_HIGH>;	/* AP2APM MAILBOX SPI NUM*/
		reg = <0x0 0x15900000 0x1000>,		/* AP2APM MAILBOX */
			<0x0 0x2039000 0x38000>;	/* APM SRAM */
		initdata-base = <0x7000>;
		num-timestamps = <32>;
		debug-log-level = <0>;
		logging-period = <500>;
		dump-base = <0x203C000>;
		dump-size = <0x35000>;			/* 212KB */
		board-id = <0x10>;			/* default - UNIV b'd */
		board-rev = <0x0>;
	};

	psci {
		compatible = "arm,psci-1.0";
		method = "smc";
	};

	cpupm {
		#define POWERMODE_TYPE_CLUSTER	0
		#define POWERMODE_TYPE_SYSTEM	1

		cpd_cl0 {
			device_type = "cpupm";
			target-residency = <10000>;
			psci-index = <128>;
			type = <POWERMODE_TYPE_CLUSTER>;
			siblings = "0-3";
		};

		cpd_cl1 {
			device_type = "cpupm";
			target-residency = <10000>;
			psci-index = <128>;
			type = <POWERMODE_TYPE_CLUSTER>;
			siblings = "4-5";
			entry-allowed = "4-5";
		};

		cpd_cl2 {
			device_type = "cpupm";
			target-residency = <10000>;
			psci-index = <128>;
			type = <POWERMODE_TYPE_CLUSTER>;
			siblings = "6-7";
			entry-allowed = "6-7";
		};

		vcpu_topology {
			vcluster_cnt = <3>;
			vcluster0_sibling = "0-3";
			vcluster1_sibling = "4-5";
			vcluster2_sibling = "6-7";
		};

		sicd {
			device_type = "cpupm";
			target-residency = <10000>;
			psci-index = <256>;
			type = <POWERMODE_TYPE_SYSTEM>;
			siblings = "0-7";
			entry-allowed = "0-3";
			system-idle;
		};

		idle-ip {
			fix-idle-ip =
				"dbg_core";
			fix-idle-ip-index =
				<0>;
		};
	};

	ufs: ufs@0x13100000 {
		/* ----------------------- */
		/* 1. SYSTEM CONFIGURATION */
		/* ----------------------- */
		compatible ="samsung,exynos-ufs";
		#address-cells = <2>;
		#size-cells = <1>;
		ranges;

		reg =
			<0x0 0x13100000 0x200>,	/* 0: HCI standard */
			<0x0 0x13101100 0x200>,	/* 1: Vendor specificed */
			<0x0 0x13180000 0x8000>,	/* 2: UNIPRO */
			<0x0 0x132A0000 0x100>;	/* 3: UFS protector */
		interrupts = <GIC_SPI INTREQ__UFS_EMBD IRQ_TYPE_LEVEL_HIGH>;
		pinctrl-names = "default";
		pinctrl-0 = <&ufs_rst_n &ufs_refclk_out>;
		clocks =
			/* aclk clock */
			<&clock GATE_UFS_EMBD>,
			/* unipro clocks */
			<&clock UFS_EMBD>;

		clock-names =
			/* aclk clocks */
			"GATE_UFS_EMBD",
			/* unipro clocks */
			"UFS_EMBD";

		/* PM QoS for INT power domain */
		ufs-pm-qos-int = <400000>;

		/* DMA coherent callback, should be coupled with 'ufs-sys' */
		dma-coherent;

		/* ----------------------- */
		/* 2. UFS COMMON           */
		/* ----------------------- */
		freq-table-hz = <0 0>, <0 0>;

		vcc-supply = <&ufs_fixed_vcc>;
		vcc-fixed-regulator;

		/* ----------------------- */
		/* 3. UFS EXYNOS           */
		/* ----------------------- */
		hw-rev = <UFS_VER_0006>;

		/* power mode change */
		ufs,pmd-attr-lane = /bits/ 8 <2>;
		ufs,pmd-attr-gear = /bits/ 8 <4>;

		/* hiberantion */
		ufs-rx-min-activate-time-cap = <3>;
		ufs-rx-hibern8-time-cap = <2>;
		ufs-tx-hibern8-time-cap = <2>;

		fmp-id = <0>;
		smu-id = <0>;

		/* ----------------------- */
		/* 4. ADDITIONAL NODES     */
		/* ----------------------- */
		/* PHY isolation */
		ufs-phy {
			#address-cells = <2>;
			#size-cells = <1>;
			ranges;
			reg = <0x0 0x13104000 0x3000>;

		};

		/* SYSREG */
		ufs-io-coherency {
			#address-cells = <2>;
			#size-cells = <1>;
			ranges;

			reg = <0x0 0x13020700 0x4>;

			mask = <(BIT_22 | BIT_23)>;
			bits = <(BIT_22 | BIT_23)>;
		};

		ufs-cport {
			reg =
			<0x0 0x13108000 0x804>;
		};

	};

	ufs_fixed_vcc: fixedregulator@0 {
		       compatible = "regulator-fixed";
		       regulator-name = "ufs-vcc";
		       gpio = <&gpg1 0 0>;
		       regulator-boot-on;
		       enable-active-high;
	};

	iommu-domain_dpu {
		compatible = "samsung,exynos-iommu-bus";
		#address-cells = <2>;
		#size-cells = <1>;
		ranges;

		domain-clients = <&dsim_0>, <&displayport>, <&dpp_6>;
	};

	iommu-domain_isp {
		compatible = "samsung,exynos-iommu-bus";
		#address-cells = <2>;
		#size-cells = <1>;
		ranges;

		domain-clients = <&exynos_is>,
				<&is_sensor0>,
				<&is_sensor1>,
				<&is_sensor2>,
				<&is_sensor3>,
				<&is_sensor4>,
				<&is_sensor5>,
				<&camerapp_gdc>;
	};

	fimg2d: g2d@18A40000 {
		compatible = "samsung,exynos9830-g2d";
		reg = <0x0 0x18A40000 0xA000>;
		interrupts = <GIC_SPI INTREQ__G2D IRQ_TYPE_LEVEL_HIGH>;
		clock-names = "gate";
		clocks = <&clock GATE_G2D>;
		iommus = <&sysmmu_g2d0>, <&sysmmu_g2d1>;
		hw_ppc =
			/* sc_up none x1 x1/4 x1/9 x1/16 */
			<3400 3100 2200 3600 5100 7000 /* rgb32 non-rotated */
			3300 2700 2000 3000 5200 6500 /* rgb32 rotated */
			3000 2900 2600 3400 5100 11900 /* yuv2p non-rotated */
			3200 2000 1900 3300 5200 7000 /* yuv2p rotated */
			2400 1900 1900 2700 3100 4100 /* 8+2 non-rotated */
			2500 900 900 2200 2900 3700 /* 8+2 rotated */
			2800>; /* colorfill */

		g2d_dvfs_table = <534000 711000
				400000 534000
				336000 400000
				267000 356000
				178000 200000
				107000 134000
				>;

		itmon,port = "G2D0", "G2D1";
		itmon,dest = "G2D";
		dma-coherent;
		dvfs_mif = <DEVFREQ_MIF>;
		dvfs_int = <DEVFREQ_INT>;
	};

	iommu-domain_g2d {
		compatible = "samsung,exynos-iommu-bus";
		#address-cells = <2>;
		#size-cells = <1>;
		ranges;

		domain-clients = <&fimg2d>;
	};

	iommu-domain_mscl_smfc {
		compatible = "samsung,exynos-iommu-bus";
		#address-cells = <2>;
		#size-cells = <1>;
		ranges;

		domain-clients = <&scaler_0>, <&smfc>, <&jsqz>;
	};

	scaler_0: scaler@18B10000 {
		compatible = "samsung,exynos5-scaler";
		reg = <0x0 0x18B10000 0x3000>;
		interrupts = <0 INTREQ__MSCL IRQ_TYPE_LEVEL_HIGH>;
		clocks = <&clock GATE_MSCL>;
		clock-names = "gate";
		itmon,master = "MSCL";
		itmon,dest = "G2D";
		dma-coherent;
		iommus = <&sysmmu_g2d2>;
	};

	smfc: smfc@18B00000 {
		compatible = "samsung,exynos8890-jpeg";
		dma-coherent;
		reg = <0x0 0x18B00000 0x1000>;
		interrupts = <0 INTREQ__JPEG IRQ_TYPE_LEVEL_HIGH>;
		clocks = <&clock GATE_JPEG>;
		clock-names = "gate";
		iommus = <&sysmmu_g2d2>;
		smfc,int_qos_minlock = <534000>;
	};

	jsqz: jsqz@18B30000 {
		compatible = "samsung,exynos-jsqz";
		//dma-coherent;
		reg = <0x0 0x18B30000 0x0200>;
		interrupts = <0 INTREQ__JSQZ 0>;
		clocks = <&clock GATE_JSQZ>;
		clock-names = "gate";
		iommus = <&sysmmu_g2d2>;
		jsqz,int_qos_minlock = <533000>;
	};

	iommu-domain_aud {
		compatible = "samsung,exynos-iommu-bus";
		#address-cells = <2>;
		#size-cells = <1>;
		ranges;

		domain-clients = <&abox>;
	};

	iommu-domain_dnc {
		compatible = "samsung,exynos-iommu-bus";
		#dma-address-cells = <1>;
		#dma-size-cells = <1>;
		dma-window = <0x80000000 0x50000000>;

		domain-clients = <&dsp>, <&npu>;
	};

	dsp: dsp@17940000 {
		compatible = "samsung,exynos-dsp";
		dma-coherent;
		reg = <0x0 0x17940000 0x100000>;
		interrupts = <GIC_SPI INTREQ__DSPC_0 IRQ_TYPE_LEVEL_HIGH>,
			     <GIC_SPI INTREQ__DSPC_1 IRQ_TYPE_LEVEL_HIGH>,
			     <GIC_SPI INTREQ__DSPC_2 IRQ_TYPE_LEVEL_HIGH>,
			     <GIC_SPI INTREQ__DSPC_3 IRQ_TYPE_LEVEL_HIGH>;
		clocks = <&clock UMUX_CLKCMU_DNC_BUS>,
			 <&clock UMUX_CLKCMU_DNC_BUSM>,
			 <&clock GATE_ADM_DAP_DNC>,
			 <&clock GATE_IP_DSPC>,
			 <&clock UMUX_CLKCMU_DSP_BUS>,
			 <&clock GATE_IP_DSP>;
		clock-names = "dnc_bus", "dnc_busm", "dnc", "dspc",
			      "dsp_bus", "dsp";
		iommus = <&sysmmu_dnc0>, <&sysmmu_dnc1>, <&sysmmu_dnc2>;
		power-domains = <&pd_dsp1>;
	};

	iommu-domain_mfc {
		compatible = "samsung,exynos-iommu-bus";
		#address-cells = <2>;
		#size-cells = <1>;
		ranges;

		domain-clients = <&mfc_0>, <&tsmux>;
	};

	tsmux: tsmux@186E0000 {
		compatible = "samsung,exynos-tsmux";
		reg = <0x0 0x186E0000 0x1000>;
		interrupts = <0 INTREQ__WFD IRQ_TYPE_LEVEL_HIGH>;
		iommus = <&sysmmu_mfc1>;
	};

	repeater: repeater@0 {
		compatible = "samsung,exynos-repeater";
		/* power domain */
		samsung,power-domain = <&pd_g2d>;
	};

	npu: npu@17800000 {
		compatible = "samsung,exynos-npu";
		iommus = <&sysmmu_dnc0>, <&sysmmu_dnc1>, <&sysmmu_dnc2>;

		interrupts = <GIC_SPI 216 IRQ_TYPE_EDGE_RISING>, <GIC_SPI 217 IRQ_TYPE_EDGE_RISING>;

		clocks = <&clock GATE_IP_NPUC_PCLK>, <&clock GATE_IP_NPUC_ACLK>, <&clock GATE_IP_DSP>, <&clock GATE_IP_DSPC>, <&clock GATE_ADM_DAP_DNC>;
		clock-names = "clk_npu", "npu_aclk", "clk_dsp", "clk_dspc", "clk_adm_dap_dnc";
		power-domains = <&pd_npu1>;
		npu_default_qos_rate = <933000>;

		reg = /* 0 start      size */
			<0 0x17B00000 0x20000>,
			<0 0x19200000 0x100000>,
			<0 0x17E00000 0x100000>,
			<0 0x17F00000 0x100000>,
			<0 0x15862900 0x100>,
			<0 0x15863400 0x400>,
			<0 0x1A350000 0xA0>,
			<0 0x17AD0000 0x17C>,
			<0 0x178C0000 0x10000>,
			<0 0x50000000 0x80000>,
			<0 0x50100000 0x200000>,
			<0 0x50300000 0x200000>;
		samsung,npumem-names =
				"TCUSRAM",
				"IDPSRAM",
				"SFR_NPU0",
				"SFR_NPU1",
				"PMU",
				"PMUCPU",
				"BAAW",
				"MAILBOX0",
				"PWM",
				"FW_DRAM",
				"FW_UNITTEST",
				"FW_LOG";

		status = "ok";
	};

	sec_pwm: pwm@106F0000 {
		compatible = "samsung,s3c6400-pwm";
		reg = <0x0 0x106F0000 0x1000>;
		samsung,pwm-outputs = <0>, <1>, <2>, <3>, <4>;
		#pwm-cells = <3>;
		clocks = <&clock GATE_PERIC0_TOP1_PWM>, <&clock OSCCLK>;
		clock-names = "pwm_pclk", "pwm_sclk";
		status = "ok";
	};

	rtc@15920000 {
		compatible = "samsung,exynos8-rtc";
		reg = <0x0 0x15920000 0x100>;
		interrupts = <GIC_SPI INTREQ__RTC_ALARM_INT IRQ_TYPE_LEVEL_HIGH>,
			     <GIC_SPI INTREQ__RTC_TIC_INT_0 IRQ_TYPE_LEVEL_HIGH>;
	};

	exynos_adc: adc@15C40000 {
		compatible = "samsung,exynos-adc-v3";
		reg = <0x0 0x15C40000 0x100>;
		interrupts = <GIC_SPI INTREQ__ADC_CMGP2AP IRQ_TYPE_LEVEL_HIGH>;
		#io-channel-cells = <1>;
		io-channel-ranges;
		clocks = <&clock GATE_ADC_CMGP_S0>;
		clock-names = "gate_adcif";
	};

	watchdog_cl0@10050000 {
		compatible = "samsung,exynos9-v3-wdt";
		reg = <0x0 0x10050000 0x100>;
		interrupts = <GIC_SPI INTREQ__WDT_CLUSTER0 IRQ_TYPE_LEVEL_HIGH>;
		clocks = <&clock OSCCLK>, <&clock GATE_WDT_CLUSTER0>;
		clock-names = "rate_watchdog", "gate_watchdog";
		timeout-sec = <30>;
		samsung,syscon-phandle = <&pmu_system_controller>;
		index = <0>; /* if little cluster then index is 0*/
	};

	watchdog_cl2@10060000 {
		compatible = "samsung,exynos9-v4-wdt";
		reg = <0x0 0x10060000 0x100>;
		interrupts = <GIC_SPI INTREQ__WDT_CLUSTER2 IRQ_TYPE_LEVEL_HIGH>;
		clocks = <&clock OSCCLK>, <&clock GATE_WDT_CLUSTER2>;
		clock-names = "rate_watchdog", "gate_watchdog";
		timeout-sec = <30>;
		samsung,syscon-phandle = <&pmu_system_controller>;
		index = <1>; /* if little cluster then index is 0*/
		use_multistage_wdt; /* Use FIQ debug watchdog */
	};

	reboot {
		compatible = "exynos,reboot";
		pmu_base = <0x15860000>;
	};

	chipid@10000000 {
		compatible = "samsung,exynos9830-chipid";
		reg = <0x0 0x10000000 0x100>;
	};

	sysreg_hsi0: sysreg_hsi0@10A20000 {
		compatible = "samsung,exynos9830-sysreg-hsi0", "syscon";
		reg = <0x0 0x10A20000 0x10000>;
	};

	udc: usb@10E00000 {
		compatible = "samsung,exynos-dwusb";
		clocks = <&clock GATE_USB31DRD_SLV_LINK>, <&clock UMUX_CLKCMU_HSI0_USB31DRD>;
		clock-names = "aclk", "sclk";
		reg = <0x0 0x10E00000 0x10000>;
		#address-cells = <2>;
		#size-cells = <1>;
		ranges;
		power-domains = <&pd_hsi0>;
		status = "disabled";
		samsung,sysreg-hsi0 = <&sysreg_hsi0>;

		usbdrd_dwc3: dwc3 {
			compatible = "synopsys,dwc3";
			reg = <0x0 0x10E00000 0x10000>;
			interrupts = <GIC_SPI INTREQ__USB31DRD_GIC0 IRQ_TYPE_LEVEL_HIGH>;
			tx-fifo-resize = <0>;
			adj-sof-accuracy = <0>;
			is_not_vbus_pad = <1>;
			enable_sprs_transfer = <1>;
			phys = <&usbdrd_phy0 0>, <&usbdrd_phy0 1>;
			phy-names = "usb2-phy", "usb3-phy";
			/* check susphy support */
			xhci_l2_support = <1>;
			dr_mode = "otg";
			/* support usb audio offloading: 1, if not: 0 */
			usb_audio_offloading = <1>;
			/* support USB L2 sleep */
			ldos = <3>;
			ldo_number = <10 11 12>;
			/* INT min lock support */
			usb-pm-qos-int = <400000>;
		};
	};

	usbdrd_phy0: phy@10C00000 {
		compatible = "samsung,exynos-usbdrd-phy";
		reg = <0x0 0x10C00000 0x200>,
			<0x0 0x10AE0000 0x2800>,
			<0x0 0x10AF0000 0x800>,
			<0x0 0x10E00000 0x10000>;
		interrupts = <GIC_SPI INTREQ__USB2_REMOTE_WAKEUP_GIC IRQ_TYPE_LEVEL_HIGH>,
			     <GIC_SPI INTREQ__USB2_REMOTE_CONNECT_GIC IRQ_TYPE_LEVEL_HIGH>;
		clocks = <&clock OSCCLK>, <&clock GATE_USB31DRD_SLV_LINK>;
		clock-names = "ext_xtal", "aclk";
		samsung,pmu-syscon = <&pmu_system_controller>;
		pmu_mask = <0x0>;
		pmu_offset = <0x72c>;
		pmu_offset_dp = <0x704>;
		/* USBDP combo phy version  - 0x200 */
		phy_version = <0x301>;
		/* if it doesn't need phy user mux, */
		/*  you should write "none" */
		/*  but refclk shouldn't be omitted */
		phyclk_mux = "none";
		phy_refclk = "ext_xtal";

		/* if Main phy has the other phy, it must be set to 1. jusf for usbphy_info */
		has_other_phy = <0>;
		/* if combo phy is used, it must be set to 1. usbphy_sub_info is enabled */
		has_combo_phy = <1>;
		sub_phy_version = <0x400>;

		/* ip type */
		/* USB3DRD = 0 */
		/*  USB3HOST = 1 */
		/*  USB2DRD = 2 */
		/*  USB2HOST = 3 */
		ip_type = <0x0>;

		/* for PHY CAL */
		/* choice only one item */
		phy_refsel_clockcore = <1>;
		phy_refsel_ext_osc = <0>;
		phy_refsel_xtal = <0>;
		phy_refsel_diff_pad = <0>;
		phy_refsel_diff_internal = <0>;
		phy_refsel_diff_single = <0>;

		/* true : 1 , false : 0 */
		use_io_for_ovc = <0>;
		common_block_disable = <1>;
		is_not_vbus_pad = <1>;
		used_phy_port = <0>;

		status = "disabled";

		#phy-cells = <1>;
		ranges;
	};

	usb_notifier {
		compatible = "samsung,usb-notifier";
		udc = <&udc>;
	};

	seclog {
		compatible = "samsung,exynos-seclog";
		interrupts = <GIC_SPI INTREQ__SECURE_LOG IRQ_TYPE_LEVEL_HIGH>;
	};

	ppmpu {
		compatible = "samsung,exynos-ppmpu";
		channel = <4>;
		irqcnt = <4>;
		interrupts = <GIC_SPI INTREQ__DMC_PPMPINT_MIF0 IRQ_TYPE_LEVEL_HIGH>,
			     <GIC_SPI INTREQ__DMC_PPMPINT_MIF1 IRQ_TYPE_LEVEL_HIGH>,
			     <GIC_SPI INTREQ__DMC_PPMPINT_MIF2 IRQ_TYPE_LEVEL_HIGH>,
			     <GIC_SPI INTREQ__DMC_PPMPINT_MIF3 IRQ_TYPE_LEVEL_HIGH>;
	};

	tzasc {
		compatible = "samsung,exynos-tzasc";
		channel = <4>;
		interleaving_shift = <0>;
		has_privileged = <0>;
		irqcnt = <4>;
		interrupts = <GIC_SPI INTREQ__DMC_TZCINT_MIF0 IRQ_TYPE_LEVEL_HIGH>,
			     <GIC_SPI INTREQ__DMC_TZCINT_MIF1 IRQ_TYPE_LEVEL_HIGH>,
			     <GIC_SPI INTREQ__DMC_TZCINT_MIF2 IRQ_TYPE_LEVEL_HIGH>,
			     <GIC_SPI INTREQ__DMC_TZCINT_MIF3 IRQ_TYPE_LEVEL_HIGH>;
	};

	/* tbase */
        tee {
                compatible = "samsung,exynos-tee";
                interrupts = <GIC_SPI INTREQ__TBASE IRQ_TYPE_LEVEL_HIGH>;
        };

	/* TEEGRIS */
	teegris {
		compatible = "samsung,teegris";
		interrupts =  <GIC_SPI INTREQ__TEEGRIS_EVENT IRQ_TYPE_LEVEL_HIGH>,
			     <GIC_SPI INTREQ__TEEGRIS_PANIC IRQ_TYPE_LEVEL_HIGH>;
	};

	/* Secure RPMB */
	ufs-srpmb {
		compatible = "samsung,ufs-srpmb";
		interrupts = <GIC_SPI INTREQ__RPMB IRQ_TYPE_LEVEL_HIGH>;
	};
	/* HDCP */
	hdcp {
		compatible = "samsung,exynos-hdcp";
		interrupts = <GIC_SPI INTREQ__HDCP IRQ_TYPE_LEVEL_HIGH>;
	};

	/* DMA */
	amba {
		#address-cells = <2>;
		#size-cells = <1>;
		compatible = "arm,amba-bus";
		interrupt-parent = <&gic>;
		ranges;
		pdma0: pdma0@1A510000 {
			compatible = "arm,pl330", "arm,primecell";
			reg = <0x0 0x1A510000 0x1000>;
			interrupts = <GIC_SPI INTREQ__PDMA IRQ_TYPE_LEVEL_HIGH>;
			clocks = <&clock GATE_PDMA>;
			clock-names = "apb_pclk";
			#dma-cells = <1>;
			#dma-channels = <8>;
			#dma-requests = <32>;
			#dma-multi-irq = <1>;
			dma-arwrapper = <0x1A514400>,
					<0x1A514420>,
					<0x1A514440>,
					<0x1A514460>,
					<0x1A514480>,
					<0x1A5144A0>,
					<0x1A5144C0>,
					<0x1A5144E0>;
			dma-awwrapper = <0x1A514404>,
					<0x1A514424>,
					<0x1A514444>,
					<0x1A514464>,
					<0x1A514484>,
					<0x1A5144A4>,
					<0x1A5144C4>,
					<0x1A5144E4>;
			dma-instwrapper = <0x1A514500>;
			dma-mask-bit = <36>;
			coherent-mask-bit = <36>;
		};
	};

	exynos-sci {
		compatible = "samsung,exynos-sci";
		acpm-ipc-channel = <10>;
		use_init_llc_region = <1>;
		initial_llc_region = <1>;	/* LLC_REGION_LIT_MID_ALL */
		ret_enable = <1>;
		llc_enable = <1>;
		region_name = "LLC_REGION_DISABLE", "LLC_REGION_LIT_MID_ALL",
			    "LLC_REGION_MFC_DISPLAY";
		region_way = <0x0 0xFFFF 0x3>;
	};

	exynos_dm: exynos-dm@17000000 {
		compatible = "samsung,exynos-dvfs-manager";
		reg = <0x0 0x17000000 0x0>;
		acpm-ipc-channel = <1>;
		dm_domains {
			cpufreq_cl0 {
				dm-index = <DM_CPU_CL0>;
				available = "true";
				cal_id = <ACPM_DVFS_CPUCL0>;
				dm_type_name = "dm_cpu_cl0";
			};
			cpufreq_cl1 {
				dm-index = <DM_CPU_CL1>;
				available = "true";
				cal_id = <ACPM_DVFS_CPUCL1>;
				dm_type_name = "dm_cpu_cl1";
			};
			cpufreq_cl2 {
				dm-index = <DM_CPU_CL2>;
				available = "true";
				cal_id = <ACPM_DVFS_CPUCL2>;
				dm_type_name = "dm_cpu_cl2";
			};
			devfreq_mif {
				dm-index = <DM_MIF>;
				available = "true";
				policy_use = "true";
				cal_id = <ACPM_DVFS_MIF>;
				dm_type_name = "dm_mif";
			};
			devfreq_int {
				dm-index = <DM_INT>;
				available = "true";
				policy_use = "true";
				cal_id = <ACPM_DVFS_INT>;
				dm_type_name = "dm_int";
			};
			devfreq_intcam {
				dm-index = <DM_INTCAM>;
				available = "true";
				cal_id = <ACPM_DVFS_INTCAM>;
				dm_type_name = "dm_intcam";
			};
			devfreq_cam {
				dm-index = <DM_CAM>;
				available = "true";
				cal_id = <ACPM_DVFS_CAM>;
				dm_type_name = "dm_cam";
			};
			devfreq_dsp {
				dm-index = <DM_DSP>;
				available = "true";
				cal_id = <ACPM_DVFS_DSP>;
				dm_type_name = "dm_dsp";
			};
			devfreq_dnc {
				dm-index = <DM_DNC>;
				available = "true";
				cal_id = <ACPM_DVFS_DNC>;
				dm_type_name = "dm_dnc";
			};
			devfreq_disp {
				dm-index = <DM_DISP>;
				available = "true";
				cal_id = <ACPM_DVFS_DISP>;
				dm_type_name = "dm_disp";
			};
			devfreq_aud {
				dm-index = <DM_AUD>;
				available = "true";
				cal_id = <ACPM_DVFS_AUD>;
				dm_type_name = "dm_aud";
			};
			devfreq_mfc {
				dm-index = <DM_MFC>;
				available = "true";
				cal_id = <ACPM_DVFS_MFC>;
				dm_type_name = "dm_mfc";
			};
			devfreq_npu {
				dm-index = <DM_NPU>;
				available = "true";
				cal_id = <ACPM_DVFS_NPU>;
				dm_type_name = "dm_npu";
			};
			dvfs_gpu {
				dm-index = <DM_GPU>;
				available = "false";
				cal_id = <ACPM_DVFS_G3D>;
				dm_type_name = "dm_gpu";
			};
			dvfs_tnr {
				dm-index = <DM_TNR>;
				available = "true";
				cal_id = <ACPM_DVFS_TNR>;
				dm_type_name = "dm_tnr";
			};
		};
	};

	exynos_devfreq {
		compatible = "samsung,exynos-devfreq-root";
		#address-cells = <2>;
		#size-cells = <1>;
		ranges;
		devfreq_0: devfreq_mif@17000010 {
			compatible = "samsung,exynos-devfreq";
			reg = <0x0 0x17000010 0x0>;
			devfreq_type = <DEVFREQ_MIF>;
			devfreq_domain_name = "MIF";
			pm_qos_class = <15>; /* PM_QOS_BUS_THROUGHPUT */
			pm_qos_class_max = <16>; /* PM_QOS_BUS_THROUGHPUT_MAX */
			ess_flag = <ESS_FLAG_MIF>;
			dm-index = <DM_MIF>;
			clocks = <&clock UMUX_MIF_DDRPHY2X>;
			clock-names = "DEVFREQ";

			/* Delay time */
			use_delay_time = "false";

			freq_info = <2028000 421000 421000 421000 2730000 1014000>;
			/* initial_freq, default_qos, suspend_freq, min_freq, max_freq reboot_freq */

			/* Booting value */
			boot_info = <40 2028000>;
			/* boot_qos_timeout, boot_freq */

			/* governor data */
			governor = <SIMPLE_INTERACTIVE>;

			dfs_id = <ACPM_DVFS_MIF>;
			acpm-ipc-channel = <1>;
			use_acpm = "true";
//			update_fvp = "true";

			/* ALT-DVFS */
			use_get_dev = "true";
			um_count = <10>;
			um_list = <0x1A100000 0x1A110000 0x1A220000 0x1A230000 0x1A120000 0x1A130000 0x1A140000 0x1A150000 0x1A160000 0x1A170000>;
			/* PPC_CPUCL2_0, PPC_CPUCL2_1, PPC_CPUCL0_0, PPC_CPUCL0_1, PPC_G3D0, PPC_G3D1, PPC_G3D2, PPCG3D3, PPC_IRPS0, PPC_IRPS1 */

			use_alt_dvfs;
			polling_ms = <0>;
			target_load = "60 676000:84 845000:90 1014000:95 1352000:97 2028000:99";
			min_sample_time = <50>;
			hold_sample_time = <100>;
			hispeed_load = <98>;
			hispeed_freq = <1014000>;
			skew {
				skew_0 {
					constraint_dm_type = <DM_INT>;
					constraint_type = <CONSTRAINT_MIN>;
				};
			};
		};

		devfreq_1: devfreq_int@17000020 {
			compatible = "samsung,exynos-devfreq";
			reg = <0x0 0x17000020 0x0>;
			devfreq_type = <DEVFREQ_INT>;
			devfreq_domain_name = "INT";
			pm_qos_class = <11>; /* PM_QOS_DEVICE_THROUGHPUT */
			pm_qos_class_max = <13>; /* PM_QOS_DEVICE_THROUGHPUT_MAX */
			ess_flag = <ESS_FLAG_INT>;
			dm-index = <DM_INT>;

			/* Delay time */
			use_delay_time = "false";

			freq_info = <533000 200000 100000 100000 533000 400000>;
			/* <initial_freq, default_qos, suspend_freq, min, max, reboot_freq> */

			/* Booting value */
			boot_info = <40 400000>;
			/* boot_qos_timeout, boot_freq */

			/* governor data */
			governor = <SIMPLE_INTERACTIVE>;

			bts_update = "false";
			dfs_id = <ACPM_DVFS_INT>;
			acpm-ipc-channel = <1>;
			use_acpm = "true";
		};

		devfreq_2: devfreq_intcam@17000030 {
			compatible = "samsung,exynos-devfreq";
			reg = <0x0 0x17000030 0x0>;
			devfreq_type = <DEVFREQ_INTCAM>;
			devfreq_domain_name = "INTCAM";
			pm_qos_class = <12>; /* PM_QOS_INTCAM_THROUGHPUT */
			pm_qos_class_max = <14>; /* PM_QOS_INTCAM_THROUGHPUT_MAX */
			ess_flag = <ESS_FLAG_INTCAM>;
			dm-index = <DM_INTCAM>;

			/* Delay time */
			use_delay_time = "false";

			freq_info = <690000 620000 620000 620000 690000 650000>;
			/* <initial_freq, default_qos, suspend_freq, min, max, reboot_freq> */

			/* Booting value */
			boot_info = <40 650000>;
			/* boot_qos_timeout, boot_freq */

			/* governor data */
			governor = <SIMPLE_INTERACTIVE>;

			bts_update = "false";
			dfs_id = <ACPM_DVFS_INTCAM>;
		};

		devfreq_3: devfreq_disp@17000040 {
			compatible = "samsung,exynos-devfreq";
			reg = <0x0 0x17000040 0x0>;
			devfreq_type = <DEVFREQ_DISP>;
			devfreq_domain_name = "DISP";
			pm_qos_class = <19>; /* PM_QOS_DISPLAY_THROUGHPUT */
			pm_qos_class_max = <20>; /* PM_QOS_DISPLAY_THROUGHPUT_MAX */
			ess_flag = <ESS_FLAG_DISP>;
			dm-index = <DM_DISP>;

			/* Delay time */
			use_delay_time = "false";

			freq_info = <666000 133000 133000 200000 666000 533000>;
			/* <initial_freq, default_qos, suspend_freq, min, max, reboot_freq> */

			/* Booting value */
			boot_info = <40 533000>;
			/* boot_qos_timeout, boot_freq */

			/* governor data */
			governor = <SIMPLE_INTERACTIVE>;

			bts_update = "false";
			dfs_id = <ACPM_DVFS_DISP>;
		};

		devfreq_4: devfreq_cam@17000050 {
			compatible = "samsung,exynos-devfreq";
			reg = <0x0 0x17000050 0x0>;
			devfreq_type = <DEVFREQ_CAM>;
			devfreq_domain_name = "CAM";
			pm_qos_class = <21>; /* PM_QOS_CAM_THROUGHPUT */
			pm_qos_class_max = <26>; /* PM_QOS_CAM_THROUGHPUT_MAX */
			ess_flag = <ESS_FLAG_ISP>;
			dm-index = <DM_CAM>;

			/* Delay time */
			use_delay_time = "false";

			freq_info = <690000 640000 640000 640000 690000 660000>;
			/* <initial, default_qos, suspend_freq, min, max, reboot_freq> */

			/* Booting value */
			boot_info = <40 660000>;
			/* boot_qos_timeout, boot_freq */

			/* governor data */
			governor = <SIMPLE_INTERACTIVE>;

			bts_update = "false";

			dfs_id = <ACPM_DVFS_CAM>;
		};

		devfreq_5: devfreq_aud@17000060 {
			compatible = "samsung,exynos-devfreq";
			reg = <0x0 0x17000060 0x0>;
			devfreq_type = <DEVFREQ_AUD>;
			devfreq_domain_name = "AUD";
			pm_qos_class = <22>; /* PM_QOS_AUD_THROUGHPUT */
			pm_qos_class_max = <27>; /* PM_QOS_AUD_THROUGHPUT_MAX */
			ess_flag = <ESS_FLAG_AUD>;
			dm-index = <DM_AUD>;

			/* Delay time */
			use_delay_time = "false";

			freq_info = <1180000 295000 295000 295000 1180000 295000>;
			/* <initial, default_qos, suspend_freq, min, max, reboot_freq> */

			/* Booting value */
			boot_info = <0 394000>;
			/* boot_qos_timeout, boot_freq */

			/* governor data */
			governor = <SIMPLE_INTERACTIVE>;

			bts_update = "false";
			dfs_id = <ACPM_DVFS_AUD>;

//			power-domains = <&pd_aud>;
			pd_name = "pd-aud";
		};

		devfreq_6: devfreq_dsp@17000070 {
			compatible = "samsung,exynos-devfreq";
			reg = <0x0 0x17000070 0x0>;
			devfreq_type = <DEVFREQ_DSP>;
			devfreq_domain_name = "DSP";
			pm_qos_class = <23>; /* PM_QOS_IVA_THROUGHPUT */
			pm_qos_class_max = <28>; /* PM_QOS_IVA_THROUGHPUT_MAX */
			ess_flag = <ESS_FLAG_DSP>;
			dm-index = <DM_DSP>;

			/* Delay time */
			use_delay_time = "false";

			freq_info = <100000 100000 100000 100000 933000 533000>;
			/* <initial, default_qos, suspend_freq, min, max, reboot_freq> */

			/* Booting value */
			boot_info = <40 533000>;
			/* boot_qos_timeout, boot_freq */

			/* governor data */
			governor = <SIMPLE_INTERACTIVE>;

			bts_update = "false";
			dfs_id = <ACPM_DVFS_DSP>;
		};

		devfreq_7: devfreq_dnc@17000080 {
			compatible = "samsung,exynos-devfreq";
			reg = <0x0 0x17000080 0x0>;
			devfreq_type = <DEVFREQ_DNC>;
			devfreq_domain_name = "DNC";
			pm_qos_class = <24>; /* PM_QOS_SCORE_THROUGHPUT */
			pm_qos_class_max = <29>; /* PM_QOS_SOCRE_THROUGHPUT_MAX */
			ess_flag = <ESS_FLAG_DNC>;
			dm-index = <DM_DNC>;

			/* Delay time */
			use_delay_time = "false";

			freq_info = <100000 100000 100000 100000 800000 100000>;
			/* <initial, default_qos, suspend_freq, min, max, reboot_freq> */

			/* Booting value */
			boot_info = <40 400000>;
			/* boot_qos_timeout, boot_freq */

			/* governor data */
			governor = <SIMPLE_INTERACTIVE>;

			bts_update = "false";
			dfs_id = <ACPM_DVFS_DNC>;
		};

		devfreq_8: devfreq_mfc@17000090 {
			compatible = "samsung,exynos-devfreq";
			reg = <0x0 0x17000090 0x0>;
			devfreq_type = <DEVFREQ_MFC>;
			devfreq_domain_name = "MFC";
			pm_qos_class = <31>; /* PM_QOS_MFC_THROUGHPUT */
			pm_qos_class_max = <33>; /* PM_QOS_MFC_THROUGHPUT_MAX */
			ess_flag = <ESS_FLAG_MFC>;
			dm-index = <DM_MFC>;

			/* Delay time */
			use_delay_time = "false";

			freq_info = <133000 133000 133000 133000 666000 133000>;
			/* <initial, default_qos, suspend_freq, min, max, reboot_freq> */

			/* Booting value */
			boot_info = <40 444000>;
			/* boot_qos_timeout, boot_freq */

			/* governor data */
			governor = <SIMPLE_INTERACTIVE>;

			bts_update = "false";
			dfs_id = <ACPM_DVFS_MFC>;
		};

		devfreq_9: devfreq_npu@170000A0 {
			compatible = "samsung,exynos-devfreq";
			reg = <0x0 0x170000A0 0x0>;
			devfreq_type = <DEVFREQ_NPU>;
			devfreq_domain_name = "NPU";
			pm_qos_class = <32>; /* PM_QOS_NPU_THROUGHPUT */
			pm_qos_class_max = <34>; /* PM_QOS_NPU_THROUGHPUT_MAX */
			ess_flag = <ESS_FLAG_NPU>;
			dm-index = <DM_NPU>;

			/* Delay time */
			use_delay_time = "false";

			freq_info = <100000 100000 100000 100000 10660000 100000>;
			/* <initial, default_qos, suspend_freq, min, max, reboot_freq> */

			/* Booting value */
			boot_info = <0 666000>;
			/* boot_qos_timeout, boot_freq */

			/* governor data */
			governor = <SIMPLE_INTERACTIVE>;

			bts_update = "false";
			dfs_id = <ACPM_DVFS_NPU>;

//			power-domains = <&pd_npu1>;
			pd_name = "pd-npu1";
		};

		devfreq_10: devfreq_tnr@170000B0 {
			compatible = "samsung,exynos-devfreq";
			reg = <0x0 0x170000B0 0x0>;
			devfreq_type = <DEVFREQ_TNR>;
			devfreq_domain_name = "TNR";
			pm_qos_class = <35>; /* PM_QOS_NPU_THROUGHPUT */
			pm_qos_class_max = <36>; /* PM_QOS_NPU_THROUGHPUT_MAX */
			ess_flag = <ESS_FLAG_TNR>;
			dm-index = <DM_TNR>;

			/* Delay time */
			use_delay_time = "false";

			freq_info = <630000 630000 630000 630000 690000 630000>;
			/* <initial, default_qos, suspend_freq, min, max, reboot_freq> */

			/* Booting value */
			boot_info = <0 660000>;
			/* boot_qos_timeout, boot_freq */

			/* governor data */
			governor = <SIMPLE_INTERACTIVE>;

			bts_update = "false";
			dfs_id = <ACPM_DVFS_TNR>;
		};
	};

	tmuctrl_0: BIG@10090000 {
		compatible = "samsung,exynos-tmu-v2";
		reg = <0x0 0x10090000 0x800>;
		interrupts = <GIC_SPI INTREQ__TMU_TMU_TOP IRQ_TYPE_LEVEL_HIGH>;
		tmu_name = "BIG";
		id = <0>;
		sensors = <62>;	/* 0x3E */
		sensing_mode = "balance";
		hotplug_enable = <1>;
		hotplug_in_threshold = <91>;
		hotplug_out_threshold = <96>;
		#thermal-sensor-cells = <0>;
	};

	tmuctrl_1: MID@10090000 {
		compatible = "samsung,exynos-tmu-v2";
		reg = <0x0 0x10090000 0x800>;
		interrupts = <GIC_SPI INTREQ__TMU_TMU_TOP IRQ_TYPE_LEVEL_HIGH>;
		tmu_name = "MID";
		id = <1>;
		sensors = <128>;		/* 0x80 */
		sensing_mode = "max";
		#thermal-sensor-cells = <0>;
	};

	tmuctrl_2: LITTLE@10090000 {
		compatible = "samsung,exynos-tmu-v2";
		reg = <0x0 0x10090000 0x800>;
		interrupts = <GIC_SPI INTREQ__TMU_TMU_TOP IRQ_TYPE_LEVEL_HIGH>;
		tmu_name = "LITTLE";
		id = <2>;
		sensors = <256>;		/* 0x100 */
		sensing_mode = "max";
		#thermal-sensor-cells = <0>;
	};

	tmuctrl_3: G3D@100A0000 {
		compatible = "samsung,exynos-tmu-v2";
		reg = <0x0 0x100A0000 0x800>;
		interrupts = <GIC_SPI INTREQ__TMU_TMU_SUB IRQ_TYPE_LEVEL_HIGH>;
		tmu_name = "G3D";
		id = <3>;
		sensors = <61>;	/* 0x3D */
		sensing_mode = "balance";
		#thermal-sensor-cells = <0>;
	};

	tmuctrl_4: ISP@100A0000 {
		compatible = "samsung,exynos-tmu-v2";
		reg = <0x0 0x100A0000 0x800>;
		interrupts = <GIC_SPI INTREQ__TMU_TMU_SUB IRQ_TYPE_LEVEL_HIGH>;
		tmu_name = "ISP";
		id = <4>;
		sensors = <256>;	/* 0x100 */
		sensing_mode = "max";
		#thermal-sensor-cells = <0>;
	};

	acpm_tmu {
		acpm-ipc-channel = <9>;
	};

	thermal-zones {
		big_thermal: BIG {
			zone_name  = "BIG_THERMAL";
			polling-delay-passive = <50>;
			polling-delay = <1000>;
			thermal-sensors = <&tmuctrl_0>;
			governor = "power_allocator";
			sustainable-power = <0>;
			k_po = <0>;
			k_pu = <0>;
			k_i = <0>;
			i_max = <0>;
			integral_cutoff = <0>;

			trips {
				big_cold: big-cold {
					temperature = <20000>;
					hysteresis = <5000>; /* millicelsius */
					type = "active";
				};
				big_switch_on: big-switch-on {
					temperature = <55000>; /* millicelsius */
					hysteresis = <2000>; /* millicelsius */
					type = "active";
				};
				big_control_temp: big-control-temp {
					temperature = <83000>; /* millicelsius */
					hysteresis = <5000>; /* millicelsius */
					type = "passive";
				};
				big_alert0: big-alert0 {
					temperature = <95000>; /* millicelsius */
					hysteresis = <5000>; /* millicelsius */
					type = "active";
				};
				big_alert1: big-alert1 {
					temperature = <100000>; /* millicelsius */
					hysteresis = <5000>; /* millicelsius */
					type = "active";
				};
				big_alert2: big-alert2 {
					temperature = <105000>; /* millicelsius */
					hysteresis = <5000>; /* millicelsius */
					type = "active";
				};
				big_alert3: big-alert3 {
					temperature = <110000>; /* millicelsius */
					hysteresis = <5000>; /* millicelsius */
					type = "active";
				};
				big_hot: big-hot {
					temperature = <115000>; /* millicelsius */
					hysteresis = <5000>; /* millicelsius */
					type = "hot";
				};
			};
			cooling-maps {
				map0 {
				     trip = <&big_control_temp>;
				     cooling-device = <&cpufreq_domain2 THERMAL_NO_LIMIT THERMAL_NO_LIMIT>;
			       };
			};
		};

		mid_thermal: MID {
			zone_name  = "MID_THERMAL";
			polling-delay-passive = <50>;
			polling-delay = <1000>;
			thermal-sensors = <&tmuctrl_1>;
			governor = "power_allocator";
			sustainable-power = <0>;
			k_po = <0>;
			k_pu = <0>;
			k_i = <0>;
			i_max = <0>;
			integral_cutoff = <0>;

			trips {
				mid_cold: mid-cold {
					temperature = <20000>;
					hysteresis = <5000>; /* millicelsius */
					type = "active";
				};
				mid_switch_on: mid-switch-on {
					temperature = <55000>; /* millicelsius */
					hysteresis = <2000>; /* millicelsius */
					type = "active";
				};
				mid_control_temp: mid-control-temp {
					temperature = <83000>; /* millicelsius */
					hysteresis = <5000>; /* millicelsius */
					type = "passive";
				};
				mid_alert0: mid-alert0 {
					temperature = <95000>; /* millicelsius */
					hysteresis = <5000>; /* millicelsius */
					type = "active";
				};
				mid_alert1: mid-alert1 {
					temperature = <100000>; /* millicelsius */
					hysteresis = <5000>; /* millicelsius */
					type = "active";
				};
				mid_alert2: mid-alert2 {
					temperature = <105000>; /* millicelsius */
					hysteresis = <5000>; /* millicelsius */
					type = "active";
				};
				mid_alert3: mid-alert3 {
					temperature = <110000>; /* millicelsius */
					hysteresis = <5000>; /* millicelsius */
					type = "active";
				};
				mid_hot: mid-hot {
					temperature = <115000>; /* millicelsius */
					hysteresis = <5000>; /* millicelsius */
					type = "hot";
				};
			};
			cooling-maps {
				map0 {
				     trip = <&mid_control_temp>;
				     cooling-device = <&cpufreq_domain1 THERMAL_NO_LIMIT THERMAL_NO_LIMIT>;
			       };
			};
		};

		little_thermal: LITTLE {
			zone_name  = "LITTLE_THERMAL";
			polling-delay-passive = <0>;
			polling-delay = <0>;
			thermal-sensors = <&tmuctrl_2>;

			trips {
				little_alert0: little-alert0 {
					temperature = <20000>; /* millicelsius */
					hysteresis = <5000>; /* millicelsius */
					type = "active";
				};
				little_alert1: little-alert1 {
					temperature = <76000>; /* millicelsius */
					hysteresis = <5000>; /* millicelsius */
					type = "active";
				};
				little_alert2: little-alert2 {
					temperature = <81000>; /* millicelsius */
					hysteresis = <5000>; /* millicelsius */
					type = "active";
				};
				little_alert3: little-alert3 {
					temperature = <86000>; /* millicelsius */
					hysteresis = <5000>; /* millicelsius */
					type = "active";
				};
				little_alert4: little-alert4 {
					temperature = <91000>; /* millicelsius */
					hysteresis = <5000>; /* millicelsius */
					type = "active";
				};
				little_alert5: little-alert5 {
					temperature = <96000>; /* millicelsius */
					hysteresis = <5000>; /* millicelsius */
					type = "active";
				};
				little_alert6: little-alert6 {
					temperature = <101000>; /* millicelsius */
					hysteresis = <5000>; /* millicelsius */
					type = "active";
				};
				little_hot: little-hot {
					temperature = <115000>; /* millicelsius */
					hysteresis = <5000>; /* millicelsius */
					type = "hot";
				};
			};
			cooling-maps {
				map0 {
				     trip = <&little_alert0>;
				     cooling-device = <&cpufreq_domain0 0 0>;
				};
				map1 {
				     trip = <&little_alert1>;
				     cooling-device = <&cpufreq_domain0 0 0>;
			       };
				map2 {
				     trip = <&little_alert2>;
				     cooling-device = <&cpufreq_domain0 0 0>;
				};
				map3 {
				     trip = <&little_alert3>;
				     cooling-device = <&cpufreq_domain0 0 0>;
				};
				map4 {
				     trip = <&little_alert4>;
				     cooling-device = <&cpufreq_domain0 0 0>;
				};
				map5 {
				     trip = <&little_alert5>;
				     cooling-device = <&cpufreq_domain0 0 0>;
			       };
				map6 {
				     trip = <&little_alert6>;
				     cooling-device = <&cpufreq_domain0 0 0>;
				};
				map7 {
				     trip = <&little_hot>;
				     cooling-device = <&cpufreq_domain0 0 0>;
				};
			};
		};

		gpu_thermal: G3D {
			zone_name  = "G3D_THERMAL";
			polling-delay-passive = <100>;
			polling-delay = <0>;
			thermal-sensors = <&tmuctrl_3>;
			governor = "power_allocator";
			sustainable-power = <0>;
			k_po = <0>;
			k_pu = <0>;
			k_i = <0>;
			i_max = <0>;
			integral_cutoff = <0>;

			trips {
				gpu_cold: gpu-cold {
					temperature = <20000>;
					hysteresis = <5000>; /* millicelsius */
					type = "active";
				};
				gpu_switch_on: gpu-switch-on {
					temperature = <78000>; /* millicelsius */
					hysteresis = <2000>; /* millicelsius */
					type = "active";
				};
				gpu_control_temp: gpu-control-temp {
					temperature = <88000>; /* millicelsius */
					hysteresis = <5000>; /* millicelsius */
					type = "passive";
				};
				gpu_alert0: gpu-alert0 {
					temperature = <105000>; /* millicelsius */
					hysteresis = <5000>; /* millicelsius */
					type = "active";
				};
				gpu_alert1: gpu-alert1 {
					temperature = <110000>; /* millicelsius */
					hysteresis = <5000>; /* millicelsius */
					type = "active";
				};
				gpu_alert2: gpu-alert2 {
					temperature = <115000>; /* millicelsius */
					hysteresis = <5000>; /* millicelsius */
					type = "active";
				};
				gpu_alert3: gpu-alert3 {
					temperature = <115000>; /* millicelsius */
					hysteresis = <5000>; /* millicelsius */
					type = "active";
				};
				gpu_hot: gpu-hot {
					temperature = <115000>; /* millicelsius */
					hysteresis = <5000>; /* millicelsius */
					type = "hot";
				};
			};
			cooling-maps {
				map0 {
				     trip = <&gpu_control_temp>;
				     cooling-device = <&mali THERMAL_NO_LIMIT THERMAL_NO_LIMIT>;
			       };
			};
		};

		isp_thermal: ISP {
			zone_name  = "ISP_THERMAL";
			polling-delay-passive = <0>;
			polling-delay = <0>;
			thermal-sensors = <&tmuctrl_4>;

			trips {
				isp_alert0: isp-alert0 {
					temperature = <20000>; /* millicelsius */
					hysteresis = <5000>; /* millicelsius */
					type = "active";
				};
				isp_alert1: isp-alert1 {
					temperature = <76000>; /* millicelsius */
					hysteresis = <5000>; /* millicelsius */
					type = "active";
				};
				isp_alert2: isp-alert2 {
					temperature = <81000>; /* millicelsius */
					hysteresis = <5000>; /* millicelsius */
					type = "active";
				};
				isp_alert3: isp-alert3 {
					temperature = <86000>; /* millicelsius */
					hysteresis = <5000>; /* millicelsius */
					type = "active";
				};
				isp_alert4: isp-alert4 {
					temperature = <91000>; /* millicelsius */
					hysteresis = <5000>; /* millicelsius */
					type = "active";
				};
				isp_alert5: isp-alert5 {
					temperature = <96000>; /* millicelsius */
					hysteresis = <5000>; /* millicelsius */
					type = "active";
				};
				isp_alert6: isp-alert6 {
					temperature = <101000>; /* millicelsius */
					hysteresis = <5000>; /* millicelsius */
					type = "active";
				};
				isp_hot: isp-hot {
					temperature = <115000>; /* millicelsius */
					hysteresis = <5000>; /* millicelsius */
					type = "hot";
				};
			};

			cooling-maps {
				map0 {
				     trip = <&isp_alert0>;
				     cooling-device = <&exynos_is 0 0>;
				};
				map1 {
				     trip = <&isp_alert1>;
				     cooling-device = <&exynos_is 0 0>;
			       };
				map2 {
				     trip = <&isp_alert2>;
				     cooling-device = <&exynos_is 0 0>;
				};
				map3 {
				     trip = <&isp_alert3>;
				     cooling-device = <&exynos_is 0 0>;
				};
				map4 {
				     trip = <&isp_alert4>;
				     cooling-device = <&exynos_is 0 0>;
				};
				map5 {
				     trip = <&isp_alert5>;
				     cooling-device = <&exynos_is 0 0>;
			       };
				map6 {
				     trip = <&isp_alert6>;
				     cooling-device = <&exynos_is 0 0>;
				};
				map7 {
				     trip = <&isp_hot>;
				     cooling-device = <&exynos_is 0 0>;
				};
			};
		};
	};

	dwmmc_2: dwmmc2@132E0000 {
		compatible = "samsung,exynos-dw-mshc";
		reg = <0x0 0x132E0000 0x2000>;
		reg-names = "dw_mmc";
		interrupts = <GIC_SPI INTREQ__MMC_CARD IRQ_TYPE_LEVEL_HIGH>;
		#address-cells = <1>;
		#size-cells = <0>;
		clocks = <&clock DOUT_CLKCMU_HSI1_MMC_CARD>, <&clock GATE_MMC_CARD>;
		clock-names = "ciu", "ciu_gate";
		status = "disabled";
	 };

	abox: abox@18c50000 {
		reg = <0x0 0x18c50000 0x10000>, <0x0 0x18c10000 0x10000>,
			<0x0 0x18d00000 0x59000>, <0x0 0x18ce0000 0x10000>;
	};

	exynos-bcmdbg {
		compatible = "samsung,exynos-bcm_dbg";

		pd-name = "pd-trex", "pd-aud", "pd-csis","pd-mcsc", "pd-vra","pd-dns",
			"pd-ipp", "pd-tnr", "pd-g2d", "pd-dnc", "pd-dpu", "pd-hsi0",
			"pd-mfc0", "pd-ssp", "pd-embedded_g3d";

		max_define_event = <PRE_DEFINE_EVT_MAX>;
		/* define_event_index ev0 ev1 ev2 ev3 ev4 ev5 ev6 ev7 */
		define_events = <NO_PRE_DEFINE_EVT	0x0  0x0  0x0  0x0  0x0  0x0  0x0  0x0>,
				<LATENCY_FMT_EVT	0x4  0x2  0x26 0x24 0x5  0x3  0x27 0x25>,
				<MO_FMT_EVT		0x4  0x0  0x24 0x24 0x5  0x1  0x25 0x25>,
				<BURST_LENGTH_FMT_EVT	0x4  0x2  0x4  0x26 0x5  0x3  0x5  0x27>,
				<REQ_BLOCK_FMT_EVT	0x2  0x10 0x10 0x26 0x3  0x11 0x11 0x27>,
				<DATA_BLOCK_FMT_EVT	0x4  0x12 0x12 0x6  0x5  0x13 0x13 0x14>,
				<REQ_TYPE_FMT_EVT	0x2  0x15 0x18 0x1B 0x3  0x16 0x19 0x1C>;
		default_define_event = <LATENCY_FMT_EVT>;

		/* sm_id_mask sm_id_value */
		define_filter_id = <NO_PRE_DEFINE_EVT	0x0  0x0>,
				<LATENCY_FMT_EVT	0x0  0x0>,
				<MO_FMT_EVT		0x0  0x0>,
				<BURST_LENGTH_FMT_EVT	0x0  0x0>,
				<REQ_BLOCK_FMT_EVT	0x0  0x0>,
				<DATA_BLOCK_FMT_EVT	0x0  0x0>,
				<REQ_TYPE_FMT_EVT	0x0  0x0>;
		/* ev0 ev1 ev2 ev3 ev4 ev5 ev6 ev7 */
		define_filter_id_active = <NO_PRE_DEFINE_EVT	0x0  0x0  0x0  0x0  0x0  0x0  0x0  0x0>,
					<LATENCY_FMT_EVT	0x0  0x0  0x0  0x0  0x0  0x0  0x0  0x0>,
					<MO_FMT_EVT		0x0  0x0  0x0  0x0  0x0  0x0  0x0  0x0>,
					<BURST_LENGTH_FMT_EVT	0x0  0x0  0x0  0x0  0x0  0x0  0x0  0x0>,
					<REQ_BLOCK_FMT_EVT	0x0  0x0  0x0  0x0  0x0  0x0  0x0  0x0>,
					<DATA_BLOCK_FMT_EVT	0x0  0x0  0x0  0x0  0x0  0x0  0x0  0x0>,
					<REQ_TYPE_FMT_EVT	0x0  0x0  0x0  0x0  0x0  0x0  0x0  0x0>;
		/* sm_other_type0 sm_other_mask0 sm_other_value0 */
		define_filter_other_0 = <NO_PRE_DEFINE_EVT	0x0  0x0  0x0>,
					<LATENCY_FMT_EVT	0x0  0x0  0x0>,
					<MO_FMT_EVT		0x0  0x0  0x0>,
					<BURST_LENGTH_FMT_EVT	0x0  0x0  0x0>,
					<REQ_BLOCK_FMT_EVT	0x0  0x0  0x0>,
					<DATA_BLOCK_FMT_EVT	0x0  0x0  0x0>,
					<REQ_TYPE_FMT_EVT	0x0  0x0  0x0>;
		/* sm_other_type1 sm_other_mask1 sm_other_value1 */
		define_filter_other_1 = <NO_PRE_DEFINE_EVT	0x0  0x0  0x0>,
					<LATENCY_FMT_EVT	0x0  0x0  0x0>,
					<MO_FMT_EVT		0x0  0x0  0x0>,
					<BURST_LENGTH_FMT_EVT	0x0  0x0  0x0>,
					<REQ_BLOCK_FMT_EVT	0x0  0x0  0x0>,
					<DATA_BLOCK_FMT_EVT	0x0  0x0  0x0>,
					<REQ_TYPE_FMT_EVT	0x0  0x0  0x0>;
		/* ev0 ev1 ev2 ev3 ev4 ev5 ev6 ev7 */
		define_filter_other_active = <NO_PRE_DEFINE_EVT	0x0  0x0  0x0  0x0  0x0  0x0  0x0  0x0>,
					<LATENCY_FMT_EVT	0x0  0x0  0x0  0x0  0x0  0x0  0x0  0x0>,
					<MO_FMT_EVT		0x0  0x0  0x0  0x0  0x0  0x0  0x0  0x0>,
					<BURST_LENGTH_FMT_EVT	0x0  0x0  0x0  0x0  0x0  0x0  0x0  0x0>,
					<REQ_BLOCK_FMT_EVT	0x0  0x0  0x0  0x0  0x0  0x0  0x0  0x0>,
					<DATA_BLOCK_FMT_EVT	0x0  0x0  0x0  0x0  0x0  0x0  0x0  0x0>,
					<REQ_TYPE_FMT_EVT	0x0  0x0  0x0  0x0  0x0  0x0  0x0  0x0>;

		/* peak_mask peak_id */
		define_sample_id = <NO_PRE_DEFINE_EVT	0x0  0x0>,
				<LATENCY_FMT_EVT	0x0  0x0>,
				<MO_FMT_EVT		0x0  0x0>,
				<BURST_LENGTH_FMT_EVT	0x0  0x0>,
				<REQ_BLOCK_FMT_EVT	0x0  0x0>,
				<DATA_BLOCK_FMT_EVT	0x0  0x0>,
				<REQ_TYPE_FMT_EVT	0x0  0x0>;
		/* ev0 ev1 ev2 ev3 ev4 ev5 ev6 ev7 */
		define_sample_id_enable = <NO_PRE_DEFINE_EVT	0x0  0x0  0x0  0x0  0x0  0x0  0x0  0x0>,
					<LATENCY_FMT_EVT	0x0  0x0  0x1  0x0  0x0  0x0  0x1  0x0>,
					<MO_FMT_EVT		0x0  0x0  0x1  0x0  0x0  0x0  0x1  0x0>,
					<BURST_LENGTH_FMT_EVT	0x0  0x0  0x1  0x1  0x0  0x0  0x1  0x1>,
					<REQ_BLOCK_FMT_EVT	0x0  0x0  0x1  0x1  0x0  0x0  0x1  0x1>,
					<DATA_BLOCK_FMT_EVT	0x0  0x0  0x1  0x0  0x0  0x0  0x1  0x0>,
					<REQ_TYPE_FMT_EVT	0x0  0x0  0x0  0x0  0x0  0x0  0x0  0x0>;

		bcm_cnt_nr = <8>;
		bcm_ip_nr = <59>;
		initial_run_bcm_ip = <0>, <1>, <2>, <3>, <4>, <5>, <6>, <7>, <8>, <9>, <10>,
				<11>, <12>, <13>, <14>, <15>, <16>, <17>, <18>,	<19>, <20>,
				<21>, <22>, <23>, <24>, <25>, <26>, <27>, <28>, <29>, <30>,
				<31>, <32>, <33>, <34>, <35>, <36>, <37>, <38>, <39>, <40>,
				<41>, <42>, <43>, <44>, <45>, <46>, <47>, <48>, <49>, <50>,
				<51>, <52>, <53>, <54>, <55>, <56>, <57>, <58>;
		initial_bcm_run = <BCM_STOP>;
		/* msec (max 500msec) */
		initial_period = <1>;
		initial_bcm_mode = <BCM_MODE_INTERVAL>;
		available_stop_owner = <PANIC_HANDLE CAMERA_DRIVER MODEM_IF ITMON_HANDLE>;
		buff_size = <0x200000>;
		glb_auto_en = <1>;

		ipc_bcm_event {
			plugin-len = <5>;
			plugin-name = "BCM";
		};
	};

	pasr {
		compatible = "samsung,exynos-pasr";
	};
};
